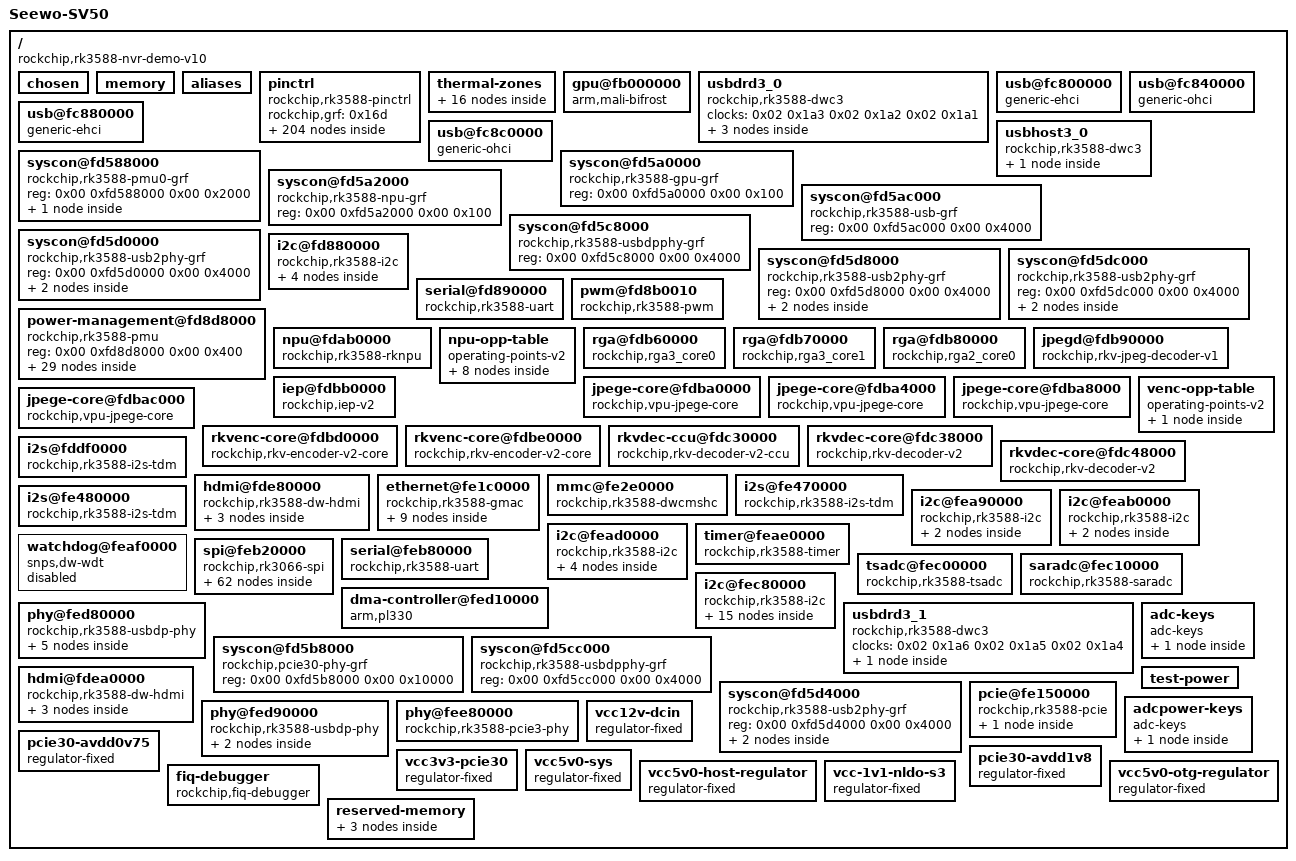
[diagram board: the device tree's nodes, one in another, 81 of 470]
/dts-v1/;

/memreserve/	0x000000000a100000 0x0000000000028000;
/ {
	compatible = "rockchip,rk3588-nvr-demo-v10\0rockchip,rk3588";
	interrupt-parent = <0x01>;
	#address-cells = <0x02>;
	#size-cells = <0x02>;
	model = "Seewo-SV50";
	
	chosen {
		bootargs = "earlycon=uart8250,mmio32,0xfeb50000 console=ttyFIQ0 irqchip.gicv3_pseudo_nmi=0 clk_gate.always_on=1 pm_domains.always_on=1";
	};

	memory {
		reg = <0x00 0x200000 0x00 0x8200000 0x00 0x9400000 0x00 0xe6c00000 0x01 0x00 0x01 0x00 0x00 0x00 0x00 0x00 0x00 0x00 0x00 0x00 0x00 0x00 0x00 0x00 0x00 0x00 0x00 0x00 0x00 0x00 0x00 0x00 0x00 0x00 0x00 0x00 0x00 0x00 0x00 0x00 0x00 0x00 0x00 0x00 0x00 0x00 0x00 0x00>;
		device_type = "memory";
	};

	aliases {
	    mmc0 = "/mmc@fe2e0000";
		ethernet ="/ethernet@fe1c0000";
	};
	
	pinctrl {
		compatible = "rockchip,rk3588-pinctrl";
		rockchip,grf = <0x16d>;
		#address-cells = <0x02>;
		#size-cells = <0x02>;
		ranges;
		phandle = <0x16e>;

		gpio@fd8a0000 {
			compatible = "rockchip,gpio-bank";
			reg = <0x00 0xfd8a0000 0x00 0x100>;
			interrupts = <0x00 0x115 0x04>;
			clocks = <0x02 0x284 0x02 0x285>;
			gpio-controller;
			#gpio-cells = <0x02>;
			gpio-ranges = <0x16e 0x00 0x00 0x20>;
			interrupt-controller;
			#interrupt-cells = <0x02>;
			phandle = <0x128>;
		};

		gpio@fec20000 {
			compatible = "rockchip,gpio-bank";
			reg = <0x00 0xfec20000 0x00 0x100>;
			interrupts = <0x00 0x116 0x04>;
			clocks = <0x02 0x7d 0x02 0x7e>;
			gpio-controller;
			#gpio-cells = <0x02>;
			gpio-ranges = <0x16e 0x00 0x20 0x20>;
			interrupt-controller;
			#interrupt-cells = <0x02>;
			phandle = <0xf1>;
		};

		gpio@fec30000 {
			compatible = "rockchip,gpio-bank";
			reg = <0x00 0xfec30000 0x00 0x100>;
			interrupts = <0x00 0x117 0x04>;
			clocks = <0x02 0x7f 0x02 0x80>;
			gpio-controller;
			#gpio-cells = <0x02>;
			gpio-ranges = <0x16e 0x00 0x40 0x20>;
			interrupt-controller;
			#interrupt-cells = <0x02>;
			phandle = <0x129>;
		};

		gpio@fec40000 {
			compatible = "rockchip,gpio-bank";
			reg = <0x00 0xfec40000 0x00 0x100>;
			interrupts = <0x00 0x118 0x04>;
			clocks = <0x02 0x81 0x02 0x82>;
			gpio-controller;
			#gpio-cells = <0x02>;
			gpio-ranges = <0x16e 0x00 0x60 0x20>;
			interrupt-controller;
			#interrupt-cells = <0x02>;
			phandle = <0xf5>;
		};

		gpio@fec50000 {
			compatible = "rockchip,gpio-bank";
			reg = <0x00 0xfec50000 0x00 0x100>;
			interrupts = <0x00 0x119 0x04>;
			clocks = <0x02 0x83 0x02 0x84>;
			gpio-controller;
			#gpio-cells = <0x02>;
			gpio-ranges = <0x16e 0x00 0x80 0x20>;
			interrupt-controller;
			#interrupt-cells = <0x02>;
			phandle = <0xe6>;
		};

		pcfg-pull-up {
			bias-pull-up;
			phandle = <0x174>;
		};

		pcfg-pull-none {
			bias-disable;
			phandle = <0x16f>;
		};

		pcfg-pull-none-drv-level-2 {
			bias-disable;
			drive-strength = <0x02>;
			phandle = <0x177>;
		};

		pcfg-pull-up-drv-level-1 {
			bias-pull-up;
			drive-strength = <0x01>;
			phandle = <0x176>;
		};

		pcfg-pull-up-drv-level-2 {
			bias-pull-up;
			drive-strength = <0x02>;
			phandle = <0x170>;
		};

		pcfg-pull-none-smt {
			bias-disable;
			input-schmitt-enable;
			phandle = <0x173>;
		};

		pcfg-pull-none-drv-level-1-smt {
			bias-disable;
			drive-strength = <0x01>;
			input-schmitt-enable;
			phandle = <0x172>;
		};

		pcfg-pull-none-drv-level-5-smt {
			bias-disable;
			drive-strength = <0x05>;
			input-schmitt-enable;
			phandle = <0x171>;
		};

		pcfg-output-high {
			output-high;
			phandle = <0x175>;
		};

		auddsm {

			auddsm-pins {
				rockchip,pins = <0x03 0x01 0x04 0x16f 0x03 0x02 0x04 0x16f 0x03 0x03 0x04 0x16f 0x03 0x04 0x04 0x16f>;
				phandle = <0x121>;
			};
		};

		bt1120 {

			bt1120-pins {
				rockchip,pins = <0x04 0x08 0x02 0x16f 0x04 0x00 0x02 0x16f 0x04 0x01 0x02 0x16f 0x04 0x02 0x02 0x16f 0x04 0x03 0x02 0x16f 0x04 0x04 0x02 0x16f 0x04 0x05 0x02 0x16f 0x04 0x06 0x02 0x16f 0x04 0x07 0x02 0x16f 0x04 0x0a 0x02 0x16f 0x04 0x0b 0x02 0x16f 0x04 0x0c 0x02 0x16f 0x04 0x0d 0x02 0x16f 0x04 0x0e 0x02 0x16f 0x04 0x0f 0x02 0x16f 0x04 0x10 0x02 0x16f 0x04 0x11 0x02 0x16f>;
				phandle = <0x59>;
			};
		};

		can0 {

			can0m0-pins {
				rockchip,pins = <0x00 0x10 0x0b 0x16f 0x00 0x0f 0x0b 0x16f>;
				phandle = <0x122>;
			};
		};

		can1 {

			can1m0-pins {
				rockchip,pins = <0x03 0x0d 0x09 0x16f 0x03 0x0e 0x09 0x16f>;
				phandle = <0x123>;
			};
		};

		can2 {

			can2m0-pins {
				rockchip,pins = <0x03 0x14 0x09 0x16f 0x03 0x15 0x09 0x16f>;
				phandle = <0x124>;
			};
		};

		dp0 {

			dp0m2-pins {
				rockchip,pins = <0x01 0x00 0x05 0x16f>;
				phandle = <0xdf>;
			};
		};

		dp1 {

			dp1m0-pins {
				rockchip,pins = <0x03 0x1d 0x05 0x16f>;
				phandle = <0x183>;
			};
		};

		gmac1 {

			gmac1-miim {
				rockchip,pins = <0x03 0x12 0x01 0x16f 0x03 0x13 0x01 0x16f>;
				phandle = <0xf6>;
			};

			gmac1-rx-bus2 {
				rockchip,pins = <0x03 0x07 0x01 0x16f 0x03 0x08 0x01 0x16f 0x03 0x09 0x01 0x16f>;
				phandle = <0xf8>;
			};

			gmac1-tx-bus2 {
				rockchip,pins = <0x03 0x0b 0x01 0x16f 0x03 0x0c 0x01 0x16f 0x03 0x0d 0x01 0x16f>;
				phandle = <0xf7>;
			};

			gmac1-rgmii-clk {
				rockchip,pins = <0x03 0x05 0x01 0x16f 0x03 0x04 0x01 0x16f>;
				phandle = <0xf9>;
			};

			gmac1-rgmii-bus {
				rockchip,pins = <0x03 0x02 0x01 0x16f 0x03 0x03 0x01 0x16f 0x03 0x00 0x01 0x16f 0x03 0x01 0x01 0x16f>;
				phandle = <0xfa>;
			};
		};

		hdmi {

			hdmim0-tx0-hpd {
				rockchip,pins = <0x01 0x05 0x05 0x16f>;
				phandle = <0xe2>;
			};

			hdmim0-tx0-scl {
				rockchip,pins = <0x04 0x0f 0x05 0x171>;
				phandle = <0xe3>;
			};

			hdmim0-tx0-sda {
				rockchip,pins = <0x04 0x10 0x05 0x172>;
				phandle = <0xe4>;
			};

			hdmim0-tx1-hpd {
				rockchip,pins = <0x01 0x06 0x05 0x16f>;
				phandle = <0x186>;
			};

			hdmim1-rx {
				rockchip,pins = <0x03 0x19 0x05 0x16f 0x03 0x1a 0x05 0x173 0x03 0x1b 0x05 0x173 0x03 0x1c 0x05 0x16f>;
				phandle = <0x190>;
			};

			hdmim1-tx1-scl {
				rockchip,pins = <0x03 0x16 0x05 0x171>;
				phandle = <0x187>;
			};

			hdmim1-tx1-sda {
				rockchip,pins = <0x03 0x15 0x05 0x172>;
				phandle = <0x188>;
			};
		};

		i2c0 {

			i2c0m2-xfer {
				rockchip,pins = <0x00 0x19 0x03 0x173 0x00 0x1a 0x03 0x173>;
				phandle = <0x60>;
			};
		};

		i2c1 {

			i2c1m2-xfer {
				rockchip,pins = <0x00 0x1c 0x09 0x173 0x00 0x1d 0x09 0x173>;
				phandle = <0x125>;
			};
		};

		i2c2 {

			i2c2m0-xfer {
				rockchip,pins = <0x00 0x0f 0x09 0x173 0x00 0x10 0x09 0x173>;
				phandle = <0x126>;
			};
		};

		i2c3 {

			i2c3m0-xfer {
				rockchip,pins = <0x01 0x11 0x09 0x173 0x01 0x10 0x09 0x173>;
				phandle = <0x127>;
			};
		};

		i2c4 {

			i2c4m3-xfer {
				rockchip,pins = <0x01 0x03 0x09 0x173 0x01 0x02 0x09 0x173>;
				phandle = <0x12a>;
			};
		};

		i2c5 {

			i2c5m0-xfer {
				rockchip,pins = <0x03 0x17 0x09 0x173 0x03 0x18 0x09 0x173>;
				phandle = <0x12b>;
			};
		};

		i2c6 {

			i2c6m0-xfer {
				rockchip,pins = <0x00 0x18 0x09 0x173 0x00 0x17 0x09 0x173>;
				phandle = <0x157>;
			};
		};

		i2c7 {

			i2c7m0-xfer {
				rockchip,pins = <0x01 0x18 0x09 0x173 0x01 0x19 0x09 0x173>;
				phandle = <0x15d>;
			};
		};

		i2c8 {

			i2c8m0-xfer {
				rockchip,pins = <0x04 0x1a 0x09 0x173 0x04 0x1b 0x09 0x173>;
				phandle = <0x15e>;
			};
		};

		i2s0 {

			i2s0-lrck {
				rockchip,pins = <0x01 0x15 0x01 0x16f>;
				phandle = <0x101>;
			};

			i2s0-sclk {
				rockchip,pins = <0x01 0x13 0x01 0x16f>;
				phandle = <0x102>;
			};

			i2s0-sdo0 {
				rockchip,pins = <0x01 0x17 0x01 0x16f>;
				phandle = <0x103>;
			};
		};

		i2s1 {

			i2s1m0-lrck {
				rockchip,pins = <0x04 0x02 0x03 0x16f>;
				phandle = <0x104>;
			};

			i2s1m0-sclk {
				rockchip,pins = <0x04 0x01 0x03 0x16f>;
				phandle = <0x105>;
			};

			i2s1m0-sdi0 {
				rockchip,pins = <0x04 0x05 0x03 0x16f>;
				phandle = <0x106>;
			};

			i2s1m0-sdi1 {
				rockchip,pins = <0x04 0x06 0x03 0x16f>;
				phandle = <0x107>;
			};

			i2s1m0-sdi2 {
				rockchip,pins = <0x04 0x07 0x03 0x16f>;
				phandle = <0x108>;
			};

			i2s1m0-sdi3 {
				rockchip,pins = <0x04 0x08 0x03 0x16f>;
				phandle = <0x109>;
			};

			i2s1m0-sdo0 {
				rockchip,pins = <0x04 0x09 0x03 0x16f>;
				phandle = <0x10a>;
			};
		};

		i2s2 {

			i2s2m1-lrck {
				rockchip,pins = <0x03 0x0e 0x03 0x16f>;
				phandle = <0x10b>;
			};

			i2s2m1-sclk {
				rockchip,pins = <0x03 0x0d 0x03 0x16f>;
				phandle = <0x10c>;
			};

			i2s2m1-sdi {
				rockchip,pins = <0x03 0x0a 0x03 0x16f>;
				phandle = <0x10d>;
			};

			i2s2m1-sdo {
				rockchip,pins = <0x03 0x0b 0x03 0x16f>;
				phandle = <0x10e>;
			};
		};

		i2s3 {

			i2s3-lrck {
				rockchip,pins = <0x03 0x02 0x03 0x16f>;
				phandle = <0x10f>;
			};

			i2s3-sclk {
				rockchip,pins = <0x03 0x01 0x03 0x16f>;
				phandle = <0x110>;
			};

			i2s3-sdi {
				rockchip,pins = <0x03 0x04 0x03 0x16f>;
				phandle = <0x111>;
			};

			i2s3-sdo {
				rockchip,pins = <0x03 0x03 0x03 0x16f>;
				phandle = <0x112>;
			};
		};

		pdm0 {

			pdm0m0-clk {
				rockchip,pins = <0x01 0x16 0x03 0x16f>;
				phandle = <0x113>;
			};

			pdm0m0-clk1 {
				rockchip,pins = <0x01 0x14 0x03 0x16f>;
				phandle = <0x114>;
			};

			pdm0m0-sdi0 {
				rockchip,pins = <0x01 0x1d 0x03 0x16f>;
				phandle = <0x115>;
			};

			pdm0m0-sdi1 {
				rockchip,pins = <0x01 0x19 0x03 0x16f>;
				phandle = <0x116>;
			};

			pdm0m0-sdi2 {
				rockchip,pins = <0x01 0x1a 0x03 0x16f>;
				phandle = <0x117>;
			};

			pdm0m0-sdi3 {
				rockchip,pins = <0x01 0x1b 0x03 0x16f>;
				phandle = <0x118>;
			};
		};

		pdm1 {

			pdm1m0-clk {
				rockchip,pins = <0x04 0x1d 0x02 0x16f>;
				phandle = <0x119>;
			};

			pdm1m0-clk1 {
				rockchip,pins = <0x04 0x1c 0x02 0x16f>;
				phandle = <0x11a>;
			};

			pdm1m0-sdi0 {
				rockchip,pins = <0x04 0x1b 0x02 0x16f>;
				phandle = <0x11b>;
			};

			pdm1m0-sdi1 {
				rockchip,pins = <0x04 0x1a 0x02 0x16f>;
				phandle = <0x11c>;
			};

			pdm1m0-sdi2 {
				rockchip,pins = <0x04 0x19 0x02 0x16f>;
				phandle = <0x11d>;
			};

			pdm1m0-sdi3 {
				rockchip,pins = <0x04 0x18 0x02 0x16f>;
				phandle = <0x11e>;
			};
		};

		pmic {

			pmic-pins {
				rockchip,pins = <0x00 0x07 0x00 0x174 0x00 0x02 0x01 0x16f 0x00 0x03 0x01 0x16f 0x00 0x11 0x01 0x16f 0x00 0x12 0x01 0x16f 0x00 0x13 0x01 0x16f 0x00 0x1e 0x01 0x16f>;
				phandle = <0x135>;
			};
		};

		pwm0 {

			pwm0m0-pins {
				rockchip,pins = <0x00 0x0f 0x03 0x16f>;
				phandle = <0x64>;
			};
		};

		pwm1 {

			pwm1m0-pins {
				rockchip,pins = <0x00 0x10 0x03 0x16f>;
				phandle = <0x65>;
			};
		};

		pwm2 {

			pwm2m0-pins {
				rockchip,pins = <0x00 0x14 0x03 0x16f>;
				phandle = <0x66>;
			};
		};

		pwm3 {

			pwm3m0-pins {
				rockchip,pins = <0x00 0x1c 0x03 0x16f>;
				phandle = <0x67>;
			};
		};

		pwm4 {

			pwm4m0-pins {
				rockchip,pins = <0x00 0x15 0x0b 0x16f>;
				phandle = <0x148>;
			};
		};

		pwm5 {

			pwm5m0-pins {
				rockchip,pins = <0x00 0x09 0x03 0x16f>;
				phandle = <0x149>;
			};
		};

		pwm6 {

			pwm6m0-pins {
				rockchip,pins = <0x00 0x17 0x0b 0x16f>;
				phandle = <0x14a>;
			};
		};

		pwm7 {

			pwm7m0-pins {
				rockchip,pins = <0x00 0x18 0x0b 0x16f>;
				phandle = <0x14b>;
			};
		};

		pwm8 {

			pwm8m0-pins {
				rockchip,pins = <0x03 0x07 0x0b 0x16f>;
				phandle = <0x14c>;
			};
		};

		pwm9 {

			pwm9m0-pins {
				rockchip,pins = <0x03 0x08 0x0b 0x16f>;
				phandle = <0x14d>;
			};
		};

		pwm10 {

			pwm10m0-pins {
				rockchip,pins = <0x03 0x00 0x0b 0x16f>;
				phandle = <0x14e>;
			};
		};

		pwm11 {

			pwm11m0-pins {
				rockchip,pins = <0x03 0x01 0x0b 0x16f>;
				phandle = <0x14f>;
			};
		};

		pwm12 {

			pwm12m0-pins {
				rockchip,pins = <0x03 0x0d 0x0b 0x16f>;
				phandle = <0x150>;
			};
		};

		pwm13 {

			pwm13m0-pins {
				rockchip,pins = <0x03 0x0e 0x0b 0x16f>;
				phandle = <0x151>;
			};
		};

		pwm14 {

			pwm14m0-pins {
				rockchip,pins = <0x03 0x12 0x0b 0x16f>;
				phandle = <0x152>;
			};
		};

		pwm15 {

			pwm15m0-pins {
				rockchip,pins = <0x03 0x13 0x0b 0x16f>;
				phandle = <0x153>;
			};
		};

		sata {

			sata1-pm-reset {
				rockchip,pins = <0x04 0x14 0x00 0x175>;
				phandle = <0x1a7>;
			};
		};

		sdio {

			sdiom1-pins {
				rockchip,pins = <0x03 0x05 0x02 0x16f 0x03 0x04 0x02 0x16f 0x03 0x00 0x02 0x16f 0x03 0x01 0x02 0x16f 0x03 0x02 0x02 0x16f 0x03 0x03 0x02 0x16f>;
				phandle = <0xff>;
			};
		};

		sdmmc {

			sdmmc-bus4 {
				rockchip,pins = <0x04 0x18 0x01 0x170 0x04 0x19 0x01 0x170 0x04 0x1a 0x01 0x170 0x04 0x1b 0x01 0x170>;
				phandle = <0xfe>;
			};

			sdmmc-clk {
				rockchip,pins = <0x04 0x1d 0x01 0x170>;
				phandle = <0xfb>;
			};

			sdmmc-cmd {
				rockchip,pins = <0x04 0x1c 0x01 0x170>;
				phandle = <0xfc>;
			};

			sdmmc-det {
				rockchip,pins = <0x00 0x04 0x01 0x174>;
				phandle = <0xfd>;
			};
		};

		spdif0 {

			spdif0m0-tx {
				rockchip,pins = <0x01 0x0e 0x03 0x16f>;
				phandle = <0x11f>;
			};
		};

		spdif1 {

			spdif1m0-tx {
				rockchip,pins = <0x01 0x0f 0x03 0x16f>;
				phandle = <0x120>;
			};
		};

		spi0 {

			spi0m0-pins {
				rockchip,pins = <0x00 0x16 0x08 0x176 0x00 0x17 0x08 0x176 0x00 0x10 0x08 0x176>;
				phandle = <0x12f>;
			};

			spi0m0-cs0 {
				rockchip,pins = <0x00 0x19 0x08 0x176>;
				phandle = <0x12d>;
			};

			spi0m0-cs1 {
				rockchip,pins = <0x00 0x0f 0x08 0x176>;
				phandle = <0x12e>;
			};
		};

		spi1 {

			spi1m1-pins {
				rockchip,pins = <0x03 0x11 0x08 0x176 0x03 0x10 0x08 0x176 0x03 0x0f 0x08 0x176>;
				phandle = <0x132>;
			};

			spi1m1-cs0 {
				rockchip,pins = <0x03 0x12 0x08 0x176>;
				phandle = <0x130>;
			};

			spi1m1-cs1 {
				rockchip,pins = <0x03 0x13 0x08 0x176>;
				phandle = <0x131>;
			};
		};

		spi2 {

			spi2m2-pins {
				rockchip,pins = <0x00 0x05 0x01 0x176 0x00 0x0b 0x01 0x176 0x00 0x06 0x01 0x176>;
				phandle = <0x134>;
			};

			spi2m2-cs0 {
				rockchip,pins = <0x00 0x09 0x01 0x176>;
				phandle = <0x133>;
			};
		};

		spi3 {

			spi3m1-pins {
				rockchip,pins = <0x04 0x0f 0x08 0x176 0x04 0x0d 0x08 0x176 0x04 0x0e 0x08 0x176>;
				phandle = <0x13e>;
			};

			spi3m1-cs0 {
				rockchip,pins = <0x04 0x10 0x08 0x176>;
				phandle = <0x13c>;
			};

			spi3m1-cs1 {
				rockchip,pins = <0x04 0x11 0x08 0x176>;
				phandle = <0x13d>;
			};
		};

		spi4 {

			spi4m0-pins {
				rockchip,pins = <0x01 0x12 0x08 0x176 0x01 0x10 0x08 0x176 0x01 0x11 0x08 0x176>;
				phandle = <0x161>;
			};

			spi4m0-cs0 {
				rockchip,pins = <0x01 0x13 0x08 0x176>;
				phandle = <0x15f>;
			};

			spi4m0-cs1 {
				rockchip,pins = <0x01 0x14 0x08 0x176>;
				phandle = <0x160>;
			};
		};

		tsadc {

			tsadc-shut {
				rockchip,pins = <0x00 0x01 0x02 0x16f>;
				phandle = <0x155>;
			};
		};

		uart0 {

			uart0m0-xfer {
				rockchip,pins = <0x00 0x14 0x04 0x174 0x00 0x15 0x04 0x174>;
				phandle = <0x63>;
			};
		};

		uart1 {

			uart1m1-xfer {
				rockchip,pins = <0x01 0x0f 0x0a 0x174 0x01 0x0e 0x0a 0x174>;
				phandle = <0x13f>;
			};
		};

		uart2 {

			uart2m0-xfer {
				rockchip,pins = <0x00 0x0e 0x0a 0x174 0x00 0x0d 0x0a 0x174>;
				phandle = <0x1bd>;
			};

			uart2m1-xfer {
				rockchip,pins = <0x04 0x19 0x0a 0x174 0x04 0x18 0x0a 0x174>;
				phandle = <0x140>;
			};
		};

		uart3 {

			uart3m1-xfer {
				rockchip,pins = <0x03 0x0e 0x0a 0x174 0x03 0x0d 0x0a 0x174>;
				phandle = <0x141>;
			};
		};

		uart4 {

			uart4m1-xfer {
				rockchip,pins = <0x03 0x18 0x0a 0x174 0x03 0x19 0x0a 0x174>;
				phandle = <0x142>;
			};
		};

		uart5 {

			uart5m0-xfer {
				rockchip,pins = <0x04 0x1c 0x0a 0x174 0x04 0x1d 0x0a 0x174>;
				phandle = <0x143>;
			};
		};

		uart6 {

			uart6m1-xfer {
				rockchip,pins = <0x01 0x00 0x0a 0x174 0x01 0x01 0x0a 0x174>;
				phandle = <0x144>;
			};
		};

		uart7 {

			uart7m1-xfer {
				rockchip,pins = <0x03 0x11 0x0a 0x174 0x03 0x10 0x0a 0x174>;
				phandle = <0x145>;
			};
		};

		uart8 {

			uart8m1-xfer {
				rockchip,pins = <0x03 0x03 0x0a 0x174 0x03 0x02 0x0a 0x174>;
				phandle = <0x146>;
			};
		};

		uart9 {

			uart9m1-xfer {
				rockchip,pins = <0x04 0x0d 0x0a 0x174 0x04 0x0c 0x0a 0x174>;
				phandle = <0x147>;
			};
		};

		gpio-func {

			tsadc-gpio-func {
				rockchip,pins = <0x00 0x01 0x00 0x16f>;
				phandle = <0x154>;
			};
		};

		gmac0 {

			gmac0-miim {
				rockchip,pins = <0x04 0x14 0x01 0x16f 0x04 0x15 0x01 0x16f>;
				phandle = <0x19b>;
			};

			gmac0-rx-bus2 {
				rockchip,pins = <0x02 0x11 0x01 0x16f 0x02 0x12 0x01 0x16f 0x04 0x12 0x01 0x16f>;
				phandle = <0x19d>;
			};

			gmac0-tx-bus2 {
				rockchip,pins = <0x02 0x0e 0x01 0x16f 0x02 0x0f 0x01 0x16f 0x02 0x10 0x01 0x16f>;
				phandle = <0x19c>;
			};

			gmac0-rgmii-clk {
				rockchip,pins = <0x02 0x08 0x01 0x16f 0x02 0x0b 0x01 0x16f>;
				phandle = <0x19e>;
			};

			gmac0-rgmii-bus {
				rockchip,pins = <0x02 0x06 0x01 0x16f 0x02 0x07 0x01 0x16f 0x02 0x09 0x01 0x16f 0x02 0x0a 0x01 0x16f>;
				phandle = <0x19f>;
			};
		};

		dp {

			dp-hdmi-ctl {
				rockchip,pins = <0x00 0x1d 0x00 0x174 0x03 0x0a 0x00 0x174>;
			};
		};

		rtc {

			rtc-int {
				rockchip,pins = <0x00 0x0a 0x00 0x174>;
			};
		};

		usb {

			vcc5v0-host-en {
				rockchip,pins = <0x04 0x08 0x00 0x16f>;
				phandle = <0x1b9>;
			};

			vcc5v0-otg-en {
				rockchip,pins = <0x04 0x03 0x00 0x16f>;
				phandle = <0x1ba>;
			};
		};

		usb-typec {

			usbc0-int {
				rockchip,pins = <0x02 0x06 0x00 0x174>;
				phandle = <0x159>;
			};
		};

		seewo {

			seewoctl-iomux {
				rockchip,pins = <0x01 0x00 0x00 0x16f 0x01 0x18 0x00 0x16f 0x01 0x04 0x00 0x16f 0x02 0x0d 0x00 0x16f 0x02 0x14 0x00 0x16f 0x02 0x11 0x00 0x16f 0x02 0x12 0x00 0x16f 0x02 0x08 0x00 0x16f 0x02 0x0c 0x00 0x16f 0x01 0x1a 0x00 0x16f 0x01 0x1b 0x00 0x16f 0x04 0x15 0x00 0x16f 0x02 0x09 0x00 0x16f 0x01 0x1d 0x00 0x16f 0x01 0x14 0x00 0x16f 0x04 0x18 0x00 0x16f 0x01 0x19 0x00 0x16f 0x04 0x1a 0x00 0x16f 0x04 0x1b 0x00 0x16f 0x01 0x0b 0x00 0x16f 0x04 0x0d 0x00 0x16f 0x04 0x0e 0x00 0x16f 0x04 0x19 0x00 0x16f>;
				phandle = <0x1bb>;
			};
		};
	};

	thermal-zones {

		soc-thermal {
			polling-delay-passive = <0x14>;
			polling-delay = <0x3e8>;
			sustainable-power = <0x834>;
			thermal-sensors = <0x49 0x00>;

			trips {

				trip-point-0 {
					temperature = <0x124f8>;
					hysteresis = <0x7d0>;
					type = "passive";
				};

				trip-point-1 {
					temperature = <0x14c08>;
					hysteresis = <0x7d0>;
					type = "passive";
					phandle = <0x4a>;
				};

				soc-crit {
					temperature = <0x1c138>;
					hysteresis = <0x7d0>;
					type = "critical";
				};
			};

			cooling-maps {

				map0 {
					trip = <0x4a>;
					cooling-device = <0x06 0xffffffff 0xffffffff>;
					contribution = <0x400>;
				};

				map1 {
					trip = <0x4a>;
					cooling-device = <0x0a 0xffffffff 0xffffffff>;
					contribution = <0x400>;
				};

				map2 {
					trip = <0x4a>;
					cooling-device = <0x0c 0xffffffff 0xffffffff>;
					contribution = <0x400>;
				};

				map3 {
					trip = <0x4a>;
					cooling-device = <0x4b 0xffffffff 0xffffffff>;
					contribution = <0x400>;
				};
			};
		};

		bigcore0-thermal {
			polling-delay-passive = <0x14>;
			polling-delay = <0x3e8>;
			thermal-sensors = <0x49 0x01>;
		};

		bigcore1-thermal {
			polling-delay-passive = <0x14>;
			polling-delay = <0x3e8>;
			thermal-sensors = <0x49 0x02>;
		};

		littlecore-thermal {
			polling-delay-passive = <0x14>;
			polling-delay = <0x3e8>;
			thermal-sensors = <0x49 0x03>;
		};

		center-thermal {
			polling-delay-passive = <0x14>;
			polling-delay = <0x3e8>;
			thermal-sensors = <0x49 0x04>;
		};

		gpu-thermal {
			polling-delay-passive = <0x14>;
			polling-delay = <0x3e8>;
			thermal-sensors = <0x49 0x05>;
		};

		npu-thermal {
			polling-delay-passive = <0x14>;
			polling-delay = <0x3e8>;
			thermal-sensors = <0x49 0x06>;
		};
	};

	gpu@fb000000 {
		compatible = "arm,mali-bifrost";
		reg = <0x00 0xfb000000 0x00 0x200000>;
		interrupts = <0x00 0x5e 0x04 0x00 0x5d 0x04 0x00 0x5c 0x04>;
		interrupt-names = "GPU\0MMU\0JOB";
		clocks = <0x0e 0x05 0x02 0x115 0x02 0x116 0x02 0x114>;
		clock-names = "clk_mali\0clk_gpu_coregroup\0clk_gpu_stacks\0clk_gpu";
		assigned-clocks = <0x0e 0x05>;
		assigned-clock-rates = <0xbebc200>;
		power-domains = <0x4c 0x0c>;
		operating-points-v2 = <0x4d>;
		#cooling-cells = <0x02>;
		dynamic-power-coefficient = <0xba6>;
		upthreshold = <0x1e>;
		downdifferential = <0x0a>;
		status = "okay";
		mali-supply = <0x4e>;
		mem-supply = <0x4e>;
		phandle = <0x4b>;
	};

	usbdrd3_0 {
		compatible = "rockchip,rk3588-dwc3\0rockchip,rk3399-dwc3";
		clocks = <0x02 0x1a3 0x02 0x1a2 0x02 0x1a1>;
		clock-names = "ref\0suspend\0bus";
		#address-cells = <0x02>;
		#size-cells = <0x02>;
		ranges;
		status = "okay";

		usb@fc000000 {
			compatible = "snps,dwc3";
			reg = <0x00 0xfc000000 0x00 0x400000>;
			interrupts = <0x00 0xdc 0x04>;
			power-domains = <0x4c 0x1f>;
			resets = <0x02 0x2a4>;
			reset-names = "usb3-otg";
			dr_mode = "peripheral";
			phys = <0x51 0x52>;
			phy-names = "usb2-phy\0usb3-phy";
			phy_type = "utmi_wide";
			snps,dis_enblslpm_quirk;
			snps,dis-u1-entry-quirk;
			snps,dis-u2-entry-quirk;
			snps,dis-u2-freeclk-exists-quirk;
			snps,dis-del-phy-power-chg-quirk;
			snps,dis-tx-ipgap-linecheck-quirk;
			snps,parkmode-disable-ss-quirk;
			quirk-skip-phy-init;
			tx-fifo-resize;
			status = "okay";

			port {
				#address-cells = <0x01>;
				#size-cells = <0x00>;

				endpoint@0 {
					reg = <0x00>;
					remote-endpoint = <0x53>;
					phandle = <0x15a>;
				};
			};
		};
	};

	usb@fc800000 {
		compatible = "generic-ehci";
		reg = <0x00 0xfc800000 0x00 0x40000>;
		interrupts = <0x00 0xd7 0x04>;
		clocks = <0x02 0x19d 0x02 0x19e 0x54>;
		clock-names = "usbhost\0arbiter\0utmi";
		phys = <0x55>;
		phy-names = "usb2-phy";
		power-domains = <0x4c 0x1f>;
		status = "okay";
	};

	usb@fc840000 {
		compatible = "generic-ohci";
		reg = <0x00 0xfc840000 0x00 0x40000>;
		interrupts = <0x00 0xd8 0x04>;
		clocks = <0x02 0x19d 0x02 0x19e 0x54>;
		clock-names = "usbhost\0arbiter\0utmi";
		phys = <0x55>;
		phy-names = "usb2-phy";
		power-domains = <0x4c 0x1f>;
		status = "okay";
	};

	usb@fc880000 {
		compatible = "generic-ehci";
		reg = <0x00 0xfc880000 0x00 0x40000>;
		interrupts = <0x00 0xda 0x04>;
		clocks = <0x02 0x19f 0x02 0x1a0 0x56>;
		clock-names = "usbhost\0arbiter\0utmi";
		phys = <0x57>;
		phy-names = "usb2-phy";
		power-domains = <0x4c 0x1f>;
		status = "okay";
	};

	usb@fc8c0000 {
		compatible = "generic-ohci";
		reg = <0x00 0xfc8c0000 0x00 0x40000>;
		interrupts = <0x00 0xdb 0x04>;
		clocks = <0x02 0x19f 0x02 0x1a0 0x56>;
		clock-names = "usbhost\0arbiter\0utmi";
		phys = <0x57>;
		phy-names = "usb2-phy";
		power-domains = <0x4c 0x1f>;
		status = "okay";
	};

	usbhost3_0 {
		compatible = "rockchip,rk3588-dwc3\0rockchip,rk3399-dwc3";
		clocks = <0x02 0x179 0x02 0x178 0x02 0x177 0x02 0x17a 0x02 0x166 0x02 0x181>;
		clock-names = "ref\0suspend\0bus\0utmi\0php\0pipe";
		#address-cells = <0x02>;
		#size-cells = <0x02>;
		ranges;
		status = "okay";

		usb@fcd00000 {
			compatible = "snps,dwc3";
			reg = <0x00 0xfcd00000 0x00 0x400000>;
			interrupts = <0x00 0xde 0x04>;
			resets = <0x02 0x237>;
			reset-names = "usb3-host";
			dr_mode = "host";
			phys = <0x58 0x04>;
			phy-names = "usb3-phy";
			phy_type = "utmi_wide";
			snps,dis_enblslpm_quirk;
			snps,dis-u2-freeclk-exists-quirk;
			snps,dis-del-phy-power-chg-quirk;
			snps,dis-tx-ipgap-linecheck-quirk;
			snps,dis_rxdet_inp3_quirk;
			snps,parkmode-disable-ss-quirk;
			status = "okay";
		};
	};

	syscon@fd588000 {
		compatible = "rockchip,rk3588-pmu0-grf\0syscon\0simple-mfd";
		reg = <0x00 0xfd588000 0x00 0x2000>;

		reboot-mode {
			compatible = "syscon-reboot-mode";
			offset = <0x80>;
			mode-bootloader = <0x5242c301>;
			mode-charge = <0x5242c30b>;
			mode-fastboot = <0x5242c309>;
			mode-loader = <0x5242c301>;
			mode-normal = <0x5242c300>;
			mode-recovery = <0x5242c303>;
			mode-ums = <0x5242c30c>;
			mode-panic = <0x5242c307>;
			mode-watchdog = <0x5242c308>;
		};
	};

	syscon@fd5a0000 {
		compatible = "rockchip,rk3588-gpu-grf\0syscon";
		reg = <0x00 0xfd5a0000 0x00 0x100>;
		phandle = <0x50>;
	};

	syscon@fd5a2000 {
		compatible = "rockchip,rk3588-npu-grf\0syscon";
		reg = <0x00 0xfd5a2000 0x00 0x100>;
		phandle = <0x9b>;
	};

	syscon@fd5ac000 {
		compatible = "rockchip,rk3588-usb-grf\0syscon";
		reg = <0x00 0xfd5ac000 0x00 0x4000>;
		phandle = <0x5c>;
	};

	syscon@fd5c8000 {
		compatible = "rockchip,rk3588-usbdpphy-grf\0syscon";
		reg = <0x00 0xfd5c8000 0x00 0x4000>;
		phandle = <0x164>;
	};

	syscon@fd5d0000 {
		compatible = "rockchip,rk3588-usb2phy-grf\0syscon\0simple-mfd";
		reg = <0x00 0xfd5d0000 0x00 0x4000>;
		#address-cells = <0x01>;
		#size-cells = <0x01>;
		phandle = <0x163>;

		usb2-phy@0 {
			compatible = "rockchip,rk3588-usb2phy";
			reg = <0x00 0x10>;
			interrupts = <0x00 0x189 0x04>;
			resets = <0x02 0xc0047 0x02 0x488>;
			reset-names = "phy\0apb";
			clocks = <0x02 0x2b5>;
			clock-names = "phyclk";
			clock-output-names = "usb480m_phy0";
			#clock-cells = <0x00>;
			rockchip,usbctrl-grf = <0x5c>;
			status = "okay";
			phandle = <0x165>;

			otg-port {
				#phy-cells = <0x00>;
				status = "okay";
				vbus-supply = <0x5d>;
				rockchip,typec-vbus-det;
				rockchip,dis-u2-susphy;
				phandle = <0x51>;
			};
		};
	};

	syscon@fd5d8000 {
		compatible = "rockchip,rk3588-usb2phy-grf\0syscon\0simple-mfd";
		reg = <0x00 0xfd5d8000 0x00 0x4000>;
		#address-cells = <0x01>;
		#size-cells = <0x01>;

		usb2-phy@8000 {
			compatible = "rockchip,rk3588-usb2phy";
			reg = <0x8000 0x10>;
			interrupts = <0x00 0x187 0x04>;
			resets = <0x02 0xc0049 0x02 0x48a>;
			reset-names = "phy\0apb";
			clocks = <0x02 0x2b5>;
			clock-names = "phyclk";
			clock-output-names = "usb480m_phy2";
			#clock-cells = <0x00>;
			status = "okay";
			phandle = <0x54>;

			host-port {
				#phy-cells = <0x00>;
				status = "okay";
				phy-supply = <0x5e>;
				phandle = <0x55>;
			};
		};
	};

	syscon@fd5dc000 {
		compatible = "rockchip,rk3588-usb2phy-grf\0syscon\0simple-mfd";
		reg = <0x00 0xfd5dc000 0x00 0x4000>;
		#address-cells = <0x01>;
		#size-cells = <0x01>;

		usb2-phy@c000 {
			compatible = "rockchip,rk3588-usb2phy";
			reg = <0xc000 0x10>;
			interrupts = <0x00 0x188 0x04>;
			resets = <0x02 0xc004a 0x02 0x48b>;
			reset-names = "phy\0apb";
			clocks = <0x02 0x2b5>;
			clock-names = "phyclk";
			clock-output-names = "usb480m_phy3";
			#clock-cells = <0x00>;
			status = "okay";
			phandle = <0x56>;

			host-port {
				#phy-cells = <0x00>;
				status = "okay";
				phy-supply = <0x5e>;
				phandle = <0x57>;
			};
		};
	};

	i2c@fd880000 {
		compatible = "rockchip,rk3588-i2c\0rockchip,rk3399-i2c";
		reg = <0x00 0xfd880000 0x00 0x1000>;
		clocks = <0x02 0x287 0x02 0x286>;
		clock-names = "i2c\0pclk";
		interrupts = <0x00 0x13d 0x04>;
		pinctrl-names = "default";
		pinctrl-0 = <0x60>;
		#address-cells = <0x01>;
		#size-cells = <0x00>;
		status = "okay";

		rk8602@42 {
			compatible = "rockchip,rk8602";
			reg = <0x42>;
			vin-supply = <0x61>;
			regulator-compatible = "rk860x-reg";
			regulator-name = "vdd_cpu_big0_s0";
			regulator-min-microvolt = <0x86470>;
			regulator-max-microvolt = <0x100590>;
			regulator-ramp-delay = <0x8fc>;
			rockchip,suspend-voltage-selector = <0x01>;
			regulator-boot-on;
			regulator-always-on;
			phandle = <0x12>;

			regulator-state-mem {
				regulator-off-in-suspend;
			};
		};

		rk8603@43 {
			compatible = "rockchip,rk8603";
			reg = <0x43>;
			vin-supply = <0x61>;
			regulator-compatible = "rk860x-reg";
			regulator-name = "vdd_cpu_big1_s0";
			regulator-min-microvolt = <0x86470>;
			regulator-max-microvolt = <0x100590>;
			regulator-ramp-delay = <0x8fc>;
			rockchip,suspend-voltage-selector = <0x01>;
			regulator-boot-on;
			regulator-always-on;
			phandle = <0x16>;

			regulator-state-mem {
				regulator-off-in-suspend;
			};
		};
	};

	serial@fd890000 {
		compatible = "rockchip,rk3588-uart\0snps,dw-apb-uart";
		reg = <0x00 0xfd890000 0x00 0x100>;
		interrupts = <0x00 0x14b 0x04>;
		clocks = <0x02 0x2ae 0x02 0x2af>;
		clock-names = "baudclk\0apb_pclk";
		reg-shift = <0x02>;
		reg-io-width = <0x04>;
		dmas = <0x62 0x06 0x62 0x07>;
		pinctrl-names = "default";
		pinctrl-0 = <0x63>;
		status = "okay";
	};

	pwm@fd8b0010 {
		compatible = "rockchip,rk3588-pwm\0rockchip,rk3328-pwm";
		reg = <0x00 0xfd8b0010 0x00 0x10>;
		#pwm-cells = <0x03>;
		pinctrl-names = "active";
		pinctrl-0 = <0x65>;
		clocks = <0x02 0x2a5 0x02 0x2a4>;
		clock-names = "pwm\0pclk";
		status = "okay";
		phandle = <0x1bc>;
	};

	power-management@fd8d8000 {
		compatible = "rockchip,rk3588-pmu\0syscon\0simple-mfd";
		reg = <0x00 0xfd8d8000 0x00 0x400>;
		phandle = <0xbe>;

		power-controller {
			compatible = "rockchip,rk3588-power-controller";
			#power-domain-cells = <0x01>;
			#address-cells = <0x01>;
			#size-cells = <0x00>;
			status = "okay";
			phandle = <0x4c>;

			power-domain@8 {
				reg = <0x08>;
				#address-cells = <0x01>;
				#size-cells = <0x00>;

				power-domain@9 {
					reg = <0x09>;
					#address-cells = <0x01>;
					#size-cells = <0x00>;
					clocks = <0x02 0x12f 0x02 0x131 0x02 0x130 0x02 0x126>;
					pm_qos = <0x68 0x69 0x6a>;

					power-domain@10 {
						reg = <0x0a>;
						clocks = <0x02 0x12f 0x02 0x131 0x02 0x130>;
						pm_qos = <0x6b>;
					};

					power-domain@11 {
						reg = <0x0b>;
						clocks = <0x02 0x12f 0x02 0x131 0x02 0x130>;
						pm_qos = <0x6c>;
					};
				};
			};

			power-domain@12 {
				reg = <0x0c>;
				clocks = <0x02 0x114 0x02 0x115 0x02 0x116>;
				pm_qos = <0x6d 0x6e 0x6f 0x70>;
			};

			power-domain@13 {
				reg = <0x0d>;
				#address-cells = <0x01>;
				#size-cells = <0x00>;

				power-domain@14 {
					reg = <0x0e>;
					clocks = <0x02 0x18f 0x02 0x1be 0x02 0x1bc 0x02 0x190 0x02 0x18e>;
					pm_qos = <0x71>;
				};

				power-domain@15 {
					reg = <0x0f>;
					clocks = <0x02 0x194 0x02 0x1be 0x02 0x1bc 0x02 0x195>;
					pm_qos = <0x72>;
				};

				power-domain@16 {
					reg = <0x10>;
					#address-cells = <0x01>;
					#size-cells = <0x00>;
					clocks = <0x02 0x1c4 0x02 0x1c5>;
					pm_qos = <0x73 0x74 0x75>;

					power-domain@17 {
						reg = <0x11>;
						clocks = <0x02 0x1c9 0x02 0x1c4 0x02 0x1c5 0x02 0x1ca>;
						pm_qos = <0x76 0x77 0x78>;
					};
				};
			};

			power-domain@21 {
				reg = <0x15>;
				#address-cells = <0x01>;
				#size-cells = <0x00>;
				clocks = <0x02 0x1be 0x02 0x1bd 0x02 0x1bc 0x02 0x1bf 0x02 0x1aa 0x02 0x1a9 0x02 0x1ac 0x02 0x1ad 0x02 0x1ae 0x02 0x1af 0x02 0x1b0 0x02 0x1b1 0x02 0x1b2 0x02 0x1b3 0x02 0x1b4 0x02 0x1b5 0x02 0x1b7 0x02 0x1b6>;
				pm_qos = <0x79 0x7a 0x7b 0x7c 0x7d 0x7e 0x7f 0x80>;

				power-domain@23 {
					reg = <0x17>;
					clocks = <0x02 0x4b 0x02 0x49 0x02 0x1be>;
					pm_qos = <0x81>;
				};

				power-domain@14 {
					reg = <0x0e>;
					clocks = <0x02 0x18f 0x02 0x1be 0x02 0x1bc 0x02 0x190>;
					pm_qos = <0x71>;
				};

				power-domain@15 {
					reg = <0x0f>;
					clocks = <0x02 0x194 0x02 0x1be 0x02 0x1bc>;
					pm_qos = <0x72>;
				};

				power-domain@22 {
					reg = <0x16>;
					clocks = <0x02 0x1ba 0x02 0x1b9>;
					pm_qos = <0x82>;
				};
			};

			power-domain@24 {
				reg = <0x18>;
				#address-cells = <0x01>;
				#size-cells = <0x00>;
				clocks = <0x02 0x26e 0x02 0x26d 0x02 0x270>;
				pm_qos = <0x83 0x84>;

				power-domain@25 {
					reg = <0x19>;
					clocks = <0x02 0x1f6 0x02 0x1f7 0x02 0x1f5 0x02 0x1f3 0x02 0x1ee 0x02 0x1ed 0x02 0x26d>;
					pm_qos = <0x85>;
				};
			};

			power-domain@26 {
				reg = <0x1a>;
				clocks = <0x02 0x22e 0x02 0x22f 0x02 0x22d 0x02 0x218 0x02 0x217 0x02 0x22b 0x02 0x264>;
				pm_qos = <0x86 0x87>;
			};

			power-domain@27 {
				reg = <0x1b>;
				#address-cells = <0x01>;
				#size-cells = <0x00>;
				clocks = <0x02 0x1e1 0x02 0x1e2 0x02 0x1df 0x02 0x1de 0x02 0x1e5 0x02 0x1e4>;
				pm_qos = <0x88 0x89 0x8a 0x8b>;

				power-domain@28 {
					reg = <0x1c>;
					clocks = <0x02 0x121 0x02 0x120 0x02 0x1e1 0x02 0x1e2>;
					pm_qos = <0x8c 0x8d>;
				};

				power-domain@29 {
					reg = <0x1d>;
					clocks = <0x02 0x1d6 0x02 0x1d5 0x02 0x1d9 0x02 0x1d8 0x02 0x1e2>;
					pm_qos = <0x8e 0x8f>;
				};
			};

			power-domain@30 {
				reg = <0x1e>;
				clocks = <0x02 0x189 0x02 0x18a>;
				pm_qos = <0x90>;
			};

			power-domain@31 {
				reg = <0x1f>;
				clocks = <0x02 0x166 0x02 0x19b 0x02 0x19c 0x02 0x19d 0x02 0x19e 0x02 0x19f 0x02 0x1a0>;
				pm_qos = <0x91 0x92 0x93 0x94>;
			};

			power-domain@33 {
				reg = <0x21>;
				clocks = <0x02 0x166 0x02 0x169 0x02 0x16a>;
			};

			power-domain@34 {
				reg = <0x22>;
				clocks = <0x02 0x166 0x02 0x169 0x02 0x16a>;
			};

			power-domain@37 {
				reg = <0x25>;
				clocks = <0x02 0x199 0x02 0x140>;
				pm_qos = <0x95>;
			};

			power-domain@38 {
				reg = <0x26>;
				clocks = <0x02 0x3c 0x02 0x3d>;
			};

			power-domain@40 {
				reg = <0x28>;
				pm_qos = <0x96>;
			};
		};
	};

	npu@fdab0000 {
		compatible = "rockchip,rk3588-rknpu";
		reg = <0x00 0xfdab0000 0x00 0x10000 0x00 0xfdac0000 0x00 0x10000 0x00 0xfdad0000 0x00 0x10000>;
		interrupts = <0x00 0x6e 0x04 0x00 0x6f 0x04 0x00 0x70 0x04>;
		interrupt-names = "npu0_irq\0npu1_irq\0npu2_irq";
		clocks = <0x0e 0x06 0x02 0x12d 0x02 0x122 0x02 0x124 0x02 0x12e 0x02 0x123 0x02 0x125 0x02 0x131>;
		clock-names = "clk_npu\0aclk0\0aclk1\0aclk2\0hclk0\0hclk1\0hclk2\0pclk";
		assigned-clocks = <0x0e 0x06>;
		assigned-clock-rates = <0xbebc200>;
		resets = <0x02 0x1e6 0x02 0x1b0 0x02 0x1c0 0x02 0x1e8 0x02 0x1b2 0x02 0x1c2>;
		reset-names = "srst_a0\0srst_a1\0srst_a2\0srst_h0\0srst_h1\0srst_h2";
		power-domains = <0x4c 0x09 0x4c 0x0a 0x4c 0x0b>;
		power-domain-names = "npu0\0npu1\0npu2";
		operating-points-v2 = <0x97>;
		iommus = <0x98>;
		status = "okay";
		rknpu-supply = <0x99>;
		mem-supply = <0x99>;
	};

	npu-opp-table {
		compatible = "operating-points-v2";
		nvmem-cells = <0x9a>;
		nvmem-cell-names = "leakage";
		rockchip,pvtm-voltage-sel = <0x00 0x32f 0x00 0x330 0x343 0x01 0x344 0x35c 0x02 0x35d 0x375 0x03 0x376 0x38e 0x04 0x38f 0x270f 0x05>;
		rockchip,pvtm-pvtpll;
		rockchip,pvtm-offset = <0x50>;
		rockchip,pvtm-sample-time = <0x44c>;
		rockchip,pvtm-freq = "\0\f5";
		rockchip,pvtm-volt = <0xb71b0>;
		rockchip,pvtm-ref-temp = <0x19>;
		rockchip,pvtm-temp-prop = <0xffffff8f 0xffffff8f>;
		rockchip,pvtm-thermal-zone = "npu-thermal";
		clocks = <0x02 0x12a>;
		clock-names = "pclk";
		rockchip,grf = <0x9b>;
		volt-mem-read-margin = <0xd0bd8 0x01 0xbac48 0x02 0xa4cb8 0x03 0x78d98 0x04>;
		low-volt-read-margin = <0x04>;
		intermediate-threshold-freq = <0x7a120>;
		rockchip,init-freq = <0xf4240>;
		rockchip,temp-hysteresis = <0x1388>;
		rockchip,low-temp = <0x2710>;
		rockchip,low-temp-min-volt = <0xb71b0>;
		rockchip,high-temp = <0x14c08>;
		rockchip,high-temp-max-freq = "\0\f5";
		phandle = <0x97>;

		opp-300000000 {
			opp-hz = <0x00 0x11e1a300>;
			opp-microvolt = <0xa4cb8 0xa4cb8 0xcf850 0xa4cb8 0xa4cb8 0xcf850>;
		};

		opp-400000000 {
			opp-hz = <0x00 0x17d78400>;
			opp-microvolt = <0xa4cb8 0xa4cb8 0xcf850 0xa4cb8 0xa4cb8 0xcf850>;
		};

		opp-500000000 {
			opp-hz = <0x00 0x1dcd6500>;
			opp-microvolt = <0xa4cb8 0xa4cb8 0xcf850 0xa4cb8 0xa4cb8 0xcf850>;
		};

		opp-600000000 {
			opp-hz = <0x00 0x23c34600>;
			opp-microvolt = <0xa4cb8 0xa4cb8 0xcf850 0xa4cb8 0xa4cb8 0xcf850>;
		};

		opp-700000000 {
			opp-hz = <0x00 0x29b92700>;
			opp-microvolt = <0xaae60 0xaae60 0xcf850 0xaae60 0xaae60 0xcf850>;
			opp-microvolt-L3 = <0xa7d8c 0xa7d8c 0xcf850 0xa7d8c 0xa7d8c 0xcf850>;
			opp-microvolt-L4 = <0xa4cb8 0xa4cb8 0xcf850 0xa4cb8 0xa4cb8 0xcf850>;
			opp-microvolt-L5 = <0xa4cb8 0xa4cb8 0xcf850 0xa4cb8 0xa4cb8 0xcf850>;
		};

		opp-800000000 {
			opp-hz = <0x00 0x2faf0800>;
			opp-microvolt = <0xb71b0 0xb71b0 0xcf850 0xb71b0 0xb71b0 0xcf850>;
			opp-microvolt-L2 = <0xb40dc 0xb40dc 0xcf850 0xb40dc 0xb40dc 0xcf850>;
			opp-microvolt-L3 = <0xb1008 0xb1008 0xcf850 0xb1008 0xb1008 0xcf850>;
			opp-microvolt-L4 = <0xadf34 0xadf34 0xcf850 0xadf34 0xadf34 0xcf850>;
			opp-microvolt-L5 = <0xaae60 0xaae60 0xcf850 0xaae60 0xaae60 0xcf850>;
		};

		opp-900000000 {
			opp-hz = <0x00 0x35a4e900>;
			opp-microvolt = <0xc3500 0xc3500 0xcf850 0xc3500 0xc3500 0xcf850>;
			opp-microvolt-L1 = <0xc042c 0xc042c 0xcf850 0xc042c 0xc042c 0xcf850>;
			opp-microvolt-L2 = <0xbd358 0xbd358 0xcf850 0xbd358 0xbd358 0xcf850>;
			opp-microvolt-L3 = <0xba284 0xba284 0xcf850 0xba284 0xba284 0xcf850>;
			opp-microvolt-L4 = <0xb71b0 0xb71b0 0xcf850 0xb71b0 0xb71b0 0xcf850>;
			opp-microvolt-L5 = <0xb40dc 0xb40dc 0xcf850 0xb40dc 0xb40dc 0xcf850>;
		};

		opp-1000000000 {
			opp-hz = <0x00 0x3b9aca00>;
			opp-microvolt = <0xcf850 0xcf850 0xcf850 0xcf850 0xcf850 0xcf850>;
			opp-microvolt-L1 = <0xcc77c 0xcc77c 0xcf850 0xcc77c 0xcc77c 0xcf850>;
			opp-microvolt-L2 = <0xc96a8 0xc96a8 0xcf850 0xc96a8 0xc96a8 0xcf850>;
			opp-microvolt-L3 = <0xc65d4 0xc65d4 0xcf850 0xc65d4 0xc65d4 0xcf850>;
			opp-microvolt-L4 = <0xc3500 0xc3500 0xcf850 0xc3500 0xc3500 0xcf850>;
			opp-microvolt-L5 = <0xc042c 0xc042c 0xcf850 0xc042c 0xc042c 0xcf850>;
		};
	};

	rga@fdb60000 {
		compatible = "rockchip,rga3_core0";
		reg = <0x00 0xfdb60000 0x00 0x1000>;
		interrupts = <0x00 0x72 0x04>;
		interrupt-names = "rga3_core0_irq";
		clocks = <0x02 0x1ba 0x02 0x1b9 0x02 0x1bb>;
		clock-names = "aclk_rga3_0\0hclk_rga3_0\0clk_rga3_0";
		power-domains = <0x4c 0x16>;
		iommus = <0x9e>;
		status = "okay";
	};

	rga@fdb70000 {
		compatible = "rockchip,rga3_core1";
		reg = <0x00 0xfdb70000 0x00 0x1000>;
		interrupts = <0x00 0x73 0x04>;
		interrupt-names = "rga3_core1_irq";
		clocks = <0x02 0x18a 0x02 0x189 0x02 0x18b>;
		clock-names = "aclk_rga3_1\0hclk_rga3_1\0clk_rga3_1";
		power-domains = <0x4c 0x1e>;
		iommus = <0x9f>;
		status = "okay";
	};

	rga@fdb80000 {
		compatible = "rockchip,rga2_core0";
		reg = <0x00 0xfdb80000 0x00 0x1000>;
		interrupts = <0x00 0x74 0x04>;
		interrupt-names = "rga2_irq";
		clocks = <0x02 0x1b7 0x02 0x1b6 0x02 0x1b8>;
		clock-names = "aclk_rga2\0hclk_rga2\0clk_rga2";
		power-domains = <0x4c 0x15>;
		status = "okay";
	};

	jpegd@fdb90000 {
		compatible = "rockchip,rkv-jpeg-decoder-v1";
		reg = <0x00 0xfdb90000 0x00 0x400>;
		interrupts = <0x00 0x81 0x04>;
		interrupt-names = "irq_jpegd";
		clocks = <0x02 0x1b4 0x02 0x1b5>;
		clock-names = "aclk_vcodec\0hclk_vcodec";
		rockchip,normal-rates = <0x23c34600 0x00>;
		assigned-clocks = <0x02 0x1b4>;
		assigned-clock-rates = <0x23c34600>;
		resets = <0x02 0x2d2 0x02 0x2d3>;
		reset-names = "video_a\0video_h";
		rockchip,skip-pmu-idle-request;
		iommus = <0xa0>;
		rockchip,srv = <0x9d>;
		rockchip,taskqueue-node = <0x01>;
		power-domains = <0x4c 0x15>;
		status = "okay";
	};

	jpege-core@fdba0000 {
		compatible = "rockchip,vpu-jpege-core";
		reg = <0x00 0xfdba0000 0x00 0x400>;
		interrupts = <0x00 0x7a 0x04>;
		interrupt-names = "irq_jpege0";
		clocks = <0x02 0x1ac 0x02 0x1ad>;
		clock-names = "aclk_vcodec\0hclk_vcodec";
		rockchip,normal-rates = <0x2367b880 0x00>;
		assigned-clocks = <0x02 0x1ac>;
		assigned-clock-rates = <0x2367b880>;
		resets = <0x02 0x2ca 0x02 0x2cb>;
		reset-names = "video_a\0video_h";
		rockchip,skip-pmu-idle-request;
		iommus = <0xa1>;
		rockchip,srv = <0x9d>;
		rockchip,taskqueue-node = <0x02>;
		rockchip,ccu = <0xa2>;
		power-domains = <0x4c 0x15>;
		status = "okay";
	};

	jpege-core@fdba4000 {
		compatible = "rockchip,vpu-jpege-core";
		reg = <0x00 0xfdba4000 0x00 0x400>;
		interrupts = <0x00 0x7c 0x04>;
		interrupt-names = "irq_jpege1";
		clocks = <0x02 0x1ae 0x02 0x1af>;
		clock-names = "aclk_vcodec\0hclk_vcodec";
		rockchip,normal-rates = <0x2367b880 0x00>;
		assigned-clocks = <0x02 0x1ae>;
		assigned-clock-rates = <0x2367b880>;
		resets = <0x02 0x2cc 0x02 0x2cd>;
		reset-names = "video_a\0video_h";
		rockchip,skip-pmu-idle-request;
		iommus = <0xa3>;
		rockchip,srv = <0x9d>;
		rockchip,taskqueue-node = <0x02>;
		rockchip,ccu = <0xa2>;
		power-domains = <0x4c 0x15>;
		status = "okay";
	};

	jpege-core@fdba8000 {
		compatible = "rockchip,vpu-jpege-core";
		reg = <0x00 0xfdba8000 0x00 0x400>;
		interrupts = <0x00 0x7e 0x04>;
		interrupt-names = "irq_jpege2";
		clocks = <0x02 0x1b0 0x02 0x1b1>;
		clock-names = "aclk_vcodec\0hclk_vcodec";
		rockchip,normal-rates = <0x2367b880 0x00>;
		assigned-clocks = <0x02 0x1b0>;
		assigned-clock-rates = <0x2367b880>;
		resets = <0x02 0x2ce 0x02 0x2cf>;
		reset-names = "video_a\0video_h";
		rockchip,skip-pmu-idle-request;
		iommus = <0xa4>;
		rockchip,srv = <0x9d>;
		rockchip,taskqueue-node = <0x02>;
		rockchip,ccu = <0xa2>;
		power-domains = <0x4c 0x15>;
		status = "okay";
	};

	jpege-core@fdbac000 {
		compatible = "rockchip,vpu-jpege-core";
		reg = <0x00 0xfdbac000 0x00 0x400>;
		interrupts = <0x00 0x80 0x04>;
		interrupt-names = "irq_jpege3";
		clocks = <0x02 0x1b2 0x02 0x1b3>;
		clock-names = "aclk_vcodec\0hclk_vcodec";
		rockchip,normal-rates = <0x2367b880 0x00>;
		assigned-clocks = <0x02 0x1b2>;
		assigned-clock-rates = <0x2367b880>;
		resets = <0x02 0x2d0 0x02 0x2d1>;
		reset-names = "video_a\0video_h";
		rockchip,skip-pmu-idle-request;
		iommus = <0xa5>;
		rockchip,srv = <0x9d>;
		rockchip,taskqueue-node = <0x02>;
		rockchip,ccu = <0xa2>;
		power-domains = <0x4c 0x15>;
		status = "okay";
	};
	
	iep@fdbb0000 {
		compatible = "rockchip,iep-v2";
		reg = <0x00 0xfdbb0000 0x00 0x500>;
		interrupts = <0x00 0x75 0x04>;
		interrupt-names = "irq_iep";
		clocks = <0x02 0x1aa 0x02 0x1a9 0x02 0x1ab>;
		clock-names = "aclk\0hclk\0sclk";
		resets = <0x02 0x2d5 0x02 0x2d4 0x02 0x2d6>;
		reset-names = "rst_a\0rst_h\0rst_s";
		rockchip,skip-pmu-idle-request;
		power-domains = <0x4c 0x15>;
		rockchip,srv = <0x9d>;
		rockchip,taskqueue-node = <0x06>;
		iommus = <0xa6>;
		status = "okay";
	};

	rkvenc-core@fdbd0000 {
		compatible = "rockchip,rkv-encoder-v2-core";
		reg = <0x00 0xfdbd0000 0x00 0x6000>;
		interrupts = <0x00 0x65 0x04>;
		interrupt-names = "irq_rkvenc0";
		clocks = <0x02 0x1c5 0x02 0x1c4 0x02 0x1c6>;
		clock-names = "aclk_vcodec\0hclk_vcodec\0clk_core";
		rockchip,normal-rates = <0x23c34600 0x00 0x2faf0800>;
		assigned-clocks = <0x02 0x1c5 0x02 0x1c6>;
		assigned-clock-rates = <0x23c34600 0x2faf0800>;
		resets = <0x02 0x2f5 0x02 0x2f4 0x02 0x2f6>;
		reset-names = "video_a\0video_h\0video_core";
		rockchip,skip-pmu-idle-request;
		iommus = <0xa7>;
		rockchip,srv = <0x9d>;
		rockchip,ccu = <0xa8>;
		rockchip,taskqueue-node = <0x07>;
		rockchip,task-capacity = <0x08>;
		power-domains = <0x4c 0x10>;
		operating-points-v2 = <0xa9>;
		status = "okay";
		venc-supply = <0xaa>;
		mem-supply = <0xaa>;
	};

	rkvenc-core@fdbe0000 {
		compatible = "rockchip,rkv-encoder-v2-core";
		reg = <0x00 0xfdbe0000 0x00 0x6000>;
		interrupts = <0x00 0x68 0x04>;
		interrupt-names = "irq_rkvenc1";
		clocks = <0x02 0x1ca 0x02 0x1c9 0x02 0x1cb>;
		clock-names = "aclk_vcodec\0hclk_vcodec\0clk_core";
		rockchip,normal-rates = <0x23c34600 0x00 0x2faf0800>;
		assigned-clocks = <0x02 0x1ca 0x02 0x1cb>;
		assigned-clock-rates = <0x23c34600 0x2faf0800>;
		resets = <0x02 0x305 0x02 0x304 0x02 0x306>;
		reset-names = "video_a\0video_h\0video_core";
		rockchip,skip-pmu-idle-request;
		iommus = <0xab>;
		rockchip,srv = <0x9d>;
		rockchip,ccu = <0xa8>;
		rockchip,taskqueue-node = <0x07>;
		rockchip,task-capacity = <0x08>;
		power-domains = <0x4c 0x11>;
		operating-points-v2 = <0xa9>;
		status = "okay";
		venc-supply = <0xaa>;
		mem-supply = <0xaa>;
	};

	venc-opp-table {
		compatible = "operating-points-v2";
		nvmem-cells = <0xac>;
		nvmem-cell-names = "leakage";
		rockchip,leakage-voltage-sel = <0x01 0x08 0x00 0x09 0x14 0x01 0x15 0xfe 0x02>;
		rockchip,grf = <0xad>;
		volt-mem-read-margin = <0xd0bd8 0x01 0xbac48 0x02 0xa4cb8 0x03 0x78d98 0x04>;
		phandle = <0xa9>;

		opp-800000000 {
			opp-hz = <0x00 0x2faf0800>;
			opp-microvolt = <0xb71b0 0xb71b0 0xcf850 0xb71b0 0xb71b0 0xcf850>;
			opp-microvolt-L0 = <0xc3500 0xc3500 0xcf850 0xc3500 0xc3500 0xcf850>;
			opp-microvolt-L1 = <0xbd358 0xbd358 0xcf850 0xbd358 0xbd358 0xcf850>;
			opp-microvolt-L2 = <0xb71b0 0xb71b0 0xcf850 0xb71b0 0xb71b0 0xcf850>;
		};
	};

	rkvdec-ccu@fdc30000 {
		compatible = "rockchip,rkv-decoder-v2-ccu";
		reg = <0x00 0xfdc30000 0x00 0x100>;
		reg-names = "ccu";
		clocks = <0x02 0x18e>;
		clock-names = "aclk_ccu";
		assigned-clocks = <0x02 0x18e>;
		assigned-clock-rates = <0x23c34600>;
		resets = <0x02 0x282>;
		reset-names = "video_ccu";
		rockchip,skip-pmu-idle-request;
		power-domains = <0x4c 0x0e>;
		status = "okay";
		phandle = <0xaf>;
	};

	rkvdec-core@fdc38000 {
		compatible = "rockchip,rkv-decoder-v2";
		reg = <0x00 0xfdc38100 0x00 0x400 0x00 0xfdc38000 0x00 0x100>;
		reg-names = "regs\0link";
		interrupts = <0x00 0x5f 0x04>;
		interrupt-names = "irq_rkvdec0";
		clocks = <0x02 0x190 0x02 0x18f 0x02 0x193 0x02 0x191 0x02 0x192>;
		clock-names = "aclk_vcodec\0hclk_vcodec\0clk_core\0clk_cabac\0clk_hevc_cabac";
		rockchip,normal-rates = <0x2faf0800 0x00 0x23c34600 0x23c34600 0x3b9aca00>;
		assigned-clocks = <0x02 0x190 0x02 0x193 0x02 0x191 0x02 0x192>;
		assigned-clock-rates = <0x2faf0800 0x23c34600 0x23c34600 0x3b9aca00>;
		resets = <0x02 0x284 0x02 0x283 0x02 0x289 0x02 0x287 0x02 0x288>;
		reset-names = "video_a\0video_h\0video_core\0video_cabac\0video_hevc_cabac";
		rockchip,skip-pmu-idle-request;
		iommus = <0xae>;
		rockchip,srv = <0x9d>;
		rockchip,ccu = <0xaf>;
		rockchip,core-mask = <0x10001>;
		rockchip,taskqueue-node = <0x09>;
		rockchip,sram = <0xb0>;
		rockchip,rcb-iova = <0x10000000 0x100000>;
		rockchip,rcb-min-width = <0x200>;
		power-domains = <0x4c 0x0e>;
		status = "okay";
	};

	rkvdec-core@fdc48000 {
		compatible = "rockchip,rkv-decoder-v2";
		reg = <0x00 0xfdc48100 0x00 0x400 0x00 0xfdc48000 0x00 0x100>;
		reg-names = "regs\0link";
		interrupts = <0x00 0x61 0x04>;
		interrupt-names = "irq_rkvdec1";
		clocks = <0x02 0x195 0x02 0x194 0x02 0x198 0x02 0x196 0x02 0x197>;
		clock-names = "aclk_vcodec\0hclk_vcodec\0clk_core\0clk_cabac\0clk_hevc_cabac";
		rockchip,normal-rates = <0x2faf0800 0x00 0x23c34600 0x23c34600 0x3b9aca00>;
		assigned-clocks = <0x02 0x195 0x02 0x198 0x02 0x196 0x02 0x197>;
		assigned-clock-rates = <0x2faf0800 0x23c34600 0x23c34600 0x3b9aca00>;
		resets = <0x02 0x293 0x02 0x292 0x02 0x298 0x02 0x296 0x02 0x297>;
		reset-names = "video_a\0video_h\0video_core\0video_cabac\0video_hevc_cabac";
		rockchip,skip-pmu-idle-request;
		iommus = <0xb1>;
		rockchip,srv = <0x9d>;
		rockchip,ccu = <0xaf>;
		rockchip,core-mask = <0x20002>;
		rockchip,taskqueue-node = <0x09>;
		rockchip,sram = <0xb2>;
		rockchip,rcb-iova = <0x10100000 0x100000>;
		rockchip,rcb-min-width = <0x200>;
		power-domains = <0x4c 0x0f>;
		status = "okay";
	};

	i2s@fddf0000 {
		compatible = "rockchip,rk3588-i2s-tdm";
		reg = <0x00 0xfddf0000 0x00 0x1000>;
		interrupts = <0x00 0xb9 0x04>;
		clocks = <0x02 0x246 0x02 0x246 0x02 0x248>;
		clock-names = "mclk_tx\0mclk_rx\0hclk";
		assigned-clocks = <0x02 0x243>;
		assigned-clock-parents = <0x02 0x05>;
		dmas = <0xd7 0x02>;
		dma-names = "tx";
		power-domains = <0x4c 0x1a>;
		resets = <0x02 0x3e8>;
		reset-names = "tx-m";
		rockchip,playback-only;
		#sound-dai-cells = <0x00>;
		status = "okay";
		phandle = <0x1ae>;
	};

	hdmi@fde80000 {
		compatible = "rockchip,rk3588-dw-hdmi";
		reg = <0x00 0xfde80000 0x00 0x20000>;
		interrupts = <0x00 0xa9 0x04 0x00 0xaa 0x04 0x00 0xab 0x04 0x00 0xac 0x04 0x00 0x168 0x04>;
		clocks = <0x02 0x221 0x02 0x265 0x02 0x222 0x02 0x223 0x02 0x246 0x02 0x274 0x02 0x275 0x02 0x276 0x02 0x277 0x05 0x2e>;
		clock-names = "pclk\0hpd\0earc\0hdmitx_ref\0aud\0dclk_vp0\0dclk_vp1\0dclk_vp2\0dclk_vp3\0hclk_vo1\0link_clk";
		resets = <0x02 0x3d0 0x02 0x49c>;
		reset-names = "ref\0hdp";
		power-domains = <0x4c 0x1a>;
		pinctrl-names = "default";
		pinctrl-0 = <0xe2 0xe3 0xe4>;
		reg-io-width = <0x04>;
		rockchip,grf = <0xad>;
		rockchip,vo1_grf = <0xbd>;
		phys = <0xe5>;
		phy-names = "hdmi";
		#sound-dai-cells = <0x00>;
		status = "okay";
		enable-gpios = <0xe6 0x09 0x00>;
		phandle = <0x1af>;

		ports {
			#address-cells = <0x01>;
			#size-cells = <0x00>;

			port@0 {
				reg = <0x00>;
				#address-cells = <0x01>;
				#size-cells = <0x00>;

				endpoint@0 {
					reg = <0x00>;
					remote-endpoint = <0x35>;
					status = "okay";
					phandle = <0xc1>;
				};
			};
		};
	};

	ethernet@fe1c0000 {
		local-mac-address = [90 e4 68 52 8e 14];
		compatible = "rockchip,rk3588-gmac\0snps,dwmac-4.20a";
		reg = <0x00 0xfe1c0000 0x00 0x10000>;
		interrupts = <0x00 0xea 0x04 0x00 0xe9 0x04>;
		interrupt-names = "macirq\0eth_wake_irq";
		rockchip,grf = <0xad>;
		rockchip,php_grf = <0x5f>;
		clocks = <0x02 0x144 0x02 0x145 0x02 0x168 0x02 0x16d 0x02 0x143>;
		clock-names = "stmmaceth\0clk_mac_ref\0pclk_mac\0aclk_mac\0ptp_ref";
		resets = <0x02 0x20b>;
		reset-names = "stmmaceth";
		power-domains = <0x4c 0x21>;
		snps,mixed-burst;
		snps,tso;
		snps,axi-config = <0xf2>;
		snps,mtl-rx-config = <0xf3>;
		snps,mtl-tx-config = <0xf4>;
		status = "okay";
		phy-mode = "rgmii";
		clock_in_out = "output";
		snps,reset-gpio = <0xf5 0x0f 0x00>;
		snps,reset-active-high;
		snps,reset-delays-us = <0x00 0x3d090 0x7a120>;
		pinctrl-names = "default";
		pinctrl-0 = <0xf6 0xf7 0xf8 0xf9 0xfa>;
		tx_delay = <0x42>;
		rx_delay = <0x4f>;
		fixed-link = <0x01 0x01 0x3e8 0x01 0x01>;

		mdio {
			compatible = "snps,dwmac-mdio";
			#address-cells = <0x01>;
			#size-cells = <0x00>;
			status = "okay";

			phy@1 {
				compatible = "ethernet-phy-ieee802.3-c22";
				reg = <0x01>;
			};
		};

		stmmac-axi-config {
			snps,wr_osr_lmt = <0x04>;
			snps,rd_osr_lmt = <0x08>;
			snps,blen = <0x00 0x00 0x00 0x00 0x10 0x08 0x04>;
			phandle = <0xf2>;
		};

		rx-queues-config {
			snps,rx-queues-to-use = <0x02>;
			phandle = <0xf3>;

			queue0 {
			};

			queue1 {
			};
		};

		tx-queues-config {
			snps,tx-queues-to-use = <0x02>;
			phandle = <0xf4>;

			queue0 {
			};

			queue1 {
			};
		};
	};

	mmc@fe2e0000 {
		compatible = "rockchip,rk3588-dwcmshc\0rockchip,dwcmshc-sdhci";
		reg = <0x00 0xfe2e0000 0x00 0x10000>;
		interrupts = <0x00 0xcd 0x04>;
		assigned-clocks = <0x02 0x13b 0x02 0x13c 0x02 0x13a>;
		assigned-clock-rates = <0xbebc200 0x16e3600 0xbebc200>;
		clocks = <0x02 0x13a 0x02 0x138 0x02 0x139 0x02 0x13b 0x02 0x13c>;
		clock-names = "core\0bus\0axi\0block\0timer";
		resets = <0x02 0x1f6 0x02 0x1f4 0x02 0x1f5 0x02 0x1f7 0x02 0x1f8>;
		reset-names = "core\0bus\0axi\0block\0timer";
		max-frequency = <0xbebc200>;
		status = "okay";
		bus-width = <0x08>;
		no-sdio;
		no-sd;
		non-removable;
		mmc-hs400-1_8v;
		mmc-hs400-enhanced-strobe;
	};

	i2s@fe470000 {
		compatible = "rockchip,rk3588-i2s-tdm";
		reg = <0x00 0xfe470000 0x00 0x1000>;
		interrupts = <0x00 0xb4 0x04>;
		clocks = <0x02 0x33 0x02 0x37 0x02 0x30>;
		clock-names = "mclk_tx\0mclk_rx\0hclk";
		assigned-clocks = <0x02 0x31 0x02 0x35>;
		assigned-clock-parents = <0x02 0x05 0x02 0x05>;
		dmas = <0x62 0x00 0x62 0x01>;
		dma-names = "tx\0rx";
		power-domains = <0x4c 0x26>;
		resets = <0x02 0x77 0x02 0x7a>;
		reset-names = "tx-m\0rx-m";
		rockchip,clk-trcm = <0x01>;
		pinctrl-names = "default";
		pinctrl-0 = <0x101 0x102 0x103>;
		#sound-dai-cells = <0x00>;
		status = "okay";
		phandle = <0x1b2>;
	};

	i2s@fe480000 {
		compatible = "rockchip,rk3588-i2s-tdm";
		reg = <0x00 0xfe480000 0x00 0x1000>;
		interrupts = <0x00 0xb5 0x04>;
		clocks = <0x02 0x28c 0x02 0x290 0x02 0x288>;
		clock-names = "mclk_tx\0mclk_rx\0hclk";
		dmas = <0x62 0x02 0x62 0x03>;
		dma-names = "tx\0rx";
		resets = <0x02 0xc002a 0x02 0xc002d>;
		reset-names = "tx-m\0rx-m";
		rockchip,clk-trcm = <0x01>;
		pinctrl-names = "default";
		pinctrl-0 = <0x104 0x105 0x106 0x107 0x108 0x109 0x10a>;
		#sound-dai-cells = <0x00>;
		status = "okay";
		assigned-clocks = <0x02 0x28f>;
		assigned-clock-parents = <0x02 0x289>;
		phandle = <0x1b5>;
	};

	i2c@fea90000 {
		compatible = "rockchip,rk3588-i2c\0rockchip,rk3399-i2c";
		reg = <0x00 0xfea90000 0x00 0x1000>;
		clocks = <0x02 0x8d 0x02 0x85>;
		clock-names = "i2c\0pclk";
		interrupts = <0x00 0x13e 0x04>;
		pinctrl-names = "default";
		pinctrl-0 = <0x125>;
		#address-cells = <0x01>;
		#size-cells = <0x00>;
		status = "okay";

		rk8602@42 {
			compatible = "rockchip,rk8602";
			reg = <0x42>;
			vin-supply = <0x61>;
			regulator-compatible = "rk860x-reg";
			regulator-name = "vdd_npu_s0";
			regulator-min-microvolt = <0x86470>;
			regulator-max-microvolt = <0xe7ef0>;
			regulator-ramp-delay = <0x8fc>;
			rockchip,suspend-voltage-selector = <0x01>;
			regulator-boot-on;
			regulator-always-on;
			phandle = <0x99>;

			regulator-state-mem {
				regulator-off-in-suspend;
			};
		};
	};

	i2c@feab0000 {
		compatible = "rockchip,rk3588-i2c\0rockchip,rk3399-i2c";
		reg = <0x00 0xfeab0000 0x00 0x1000>;
		clocks = <0x02 0x8f 0x02 0x87>;
		clock-names = "i2c\0pclk";
		interrupts = <0x00 0x140 0x04>;
		pinctrl-names = "default";
		pinctrl-0 = <0x127>;
		#address-cells = <0x01>;
		#size-cells = <0x00>;
		status = "okay";
		clock-frequency = <0x186a0>;

		lt8911exb@29 {
			status = "okay";
			compatible = "lontium,lt8911exb";
			reg = <0x29>;
			bl-on-gpios = <0x128 0x0f 0x00>;
			panel-pwren-gpios = <0x129 0x0b 0x00>;
			bl-pwren-gpios = <0x129 0x0a 0x00>;
			rst-gpios = <0xe6 0x16 0x00>;
			lt-irq-gpios = <0x129 0x15 0x00>;
		};

		acm8265m@2d {
			status = "okay";
			compatible = "ESMT, acm8625m";
			reg = <0x2d>;
			#sound-dai-cells = <0x00>;
			reset_pin = <0xf1 0x12 0x00>;
			no_mclk;
			phandle = <0x1b3>;
		};
	};

	i2c@fead0000 {
		compatible = "rockchip,rk3588-i2c\0rockchip,rk3399-i2c";
		reg = <0x00 0xfead0000 0x00 0x1000>;
		clocks = <0x02 0x91 0x02 0x89>;
		clock-names = "i2c\0pclk";
		interrupts = <0x00 0x142 0x04>;
		pinctrl-names = "default";
		pinctrl-0 = <0x12b>;
		#address-cells = <0x01>;
		#size-cells = <0x00>;
		status = "okay";

		lt6911c_A@2b {
			status = "okay";
			compatible = "lontium,lt6911c";
			reg = <0x2b>;
			clocks = <0x02 0x101>;
			clock-names = "xvclk";
			reset-gpios = <0xe6 0x11 0x00>;
			res-change-gpios = <0xf5 0x14 0x00>;
			plugin-det-gpios = <0xf5 0x19 0x00>;
			rockchip,camera-module-index = <0x00>;
			rockchip,camera-module-facing = "back";
			rockchip,camera-module-name = "lt6911c_A";
			rockchip,camera-module-lens-name = "NC";
			cvte,hdmi-port-name = "HDMIIN1";

			port {

				endpoint {
					remote-endpoint = <0x12c>;
					data-lanes = <0x01 0x02 0x03 0x04>;
					phandle = <0x2a>;
				};
			};
		};

		lt8711uxe1@29 {
			status = "okay";
			compatible = "lontium,lt8711uxe1";
			reg = <0x29>;
			plugin-det-gpios = <0xf5 0x1d 0x00>;
			reset-gpios = <0xf5 0x0e 0x00>;
		};
	};

	timer@feae0000 {
		compatible = "rockchip,rk3588-timer\0rockchip,rk3288-timer";
		reg = <0x00 0xfeae0000 0x00 0x20>;
		interrupts = <0x00 0x121 0x04>;
		clocks = <0x02 0x5c 0x02 0x5f>;
		clock-names = "pclk\0timer";
	};

	watchdog@feaf0000 {
		compatible = "snps,dw-wdt";
		reg = <0x00 0xfeaf0000 0x00 0x100>;
		clocks = <0x02 0x6c 0x02 0x6b>;
		clock-names = "tclk\0pclk";
		interrupts = <0x00 0x13b 0x04>;
		
		status = "disabled";
	};

	spi@feb20000 {
		compatible = "rockchip,rk3066-spi";
		reg = <0x00 0xfeb20000 0x00 0x1000>;
		interrupts = <0x00 0x148 0x04>;
		#address-cells = <0x01>;
		#size-cells = <0x00>;
		clocks = <0x02 0xa5 0x02 0xa0>;
		clock-names = "spiclk\0apb_pclk";
		dmas = <0xd6 0x0f 0xd6 0x10>;
		dma-names = "tx\0rx";
		pinctrl-names = "default";
		pinctrl-0 = <0x133 0x134>;
		num-cs = <0x01>;
		status = "okay";
		assigned-clocks = <0x02 0xa5>;
		assigned-clock-rates = <0xbebc200>;

		rk806single@0 {
			compatible = "rockchip,rk806";
			spi-max-frequency = <0xf4240>;
			reg = <0x00>;
			interrupt-parent = <0x128>;
			interrupts = <0x07 0x08>;
			pinctrl-names = "default\0pmic-power-off";
			pinctrl-0 = <0x135 0x136 0x137 0x138>;
			pinctrl-1 = <0x139 0x137 0x138>;
			low_voltage_threshold = <0xbb8>;
			shutdown_voltage_threshold = <0xa8c>;
			shutdown_temperture_threshold = <0xa0>;
			hotdie_temperture_threshold = <0x73>;
			pmic-reset-func = <0x01>;
			vcc1-supply = <0x61>;
			vcc2-supply = <0x61>;
			vcc3-supply = <0x61>;
			vcc4-supply = <0x61>;
			vcc5-supply = <0x61>;
			vcc6-supply = <0x61>;
			vcc7-supply = <0x61>;
			vcc8-supply = <0x61>;
			vcc9-supply = <0x61>;
			vcc10-supply = <0x61>;
			vcc11-supply = <0x13a>;
			vcc12-supply = <0x61>;
			vcc13-supply = <0x13b>;
			vcc14-supply = <0x13b>;
			vcca-supply = <0x61>;

			pwrkey {
				status = "okay";
			};

			pinctrl_rk806 {
				gpio-controller;
				#gpio-cells = <0x02>;

				rk806_dvs1_null {
					pins = "gpio_pwrctrl2";
					function = "pin_fun0";
					phandle = <0x136>;
				};

				rk806_dvs1_slp {
					pins = "gpio_pwrctrl1";
					function = "pin_fun1";
					phandle = <0x139>;
				};

				rk806_dvs1_pwrdn {
					pins = "gpio_pwrctrl1";
					function = "pin_fun2";
				};

				rk806_dvs1_rst {
					pins = "gpio_pwrctrl1";
					function = "pin_fun3";
				};

				rk806_dvs2_null {
					pins = "gpio_pwrctrl2";
					function = "pin_fun0";
					phandle = <0x137>;
				};

				rk806_dvs2_slp {
					pins = "gpio_pwrctrl2";
					function = "pin_fun1";
				};

				rk806_dvs2_pwrdn {
					pins = "gpio_pwrctrl2";
					function = "pin_fun2";
				};

				rk806_dvs2_rst {
					pins = "gpio_pwrctrl2";
					function = "pin_fun3";
				};

				rk806_dvs2_dvs {
					pins = "gpio_pwrctrl2";
					function = "pin_fun4";
				};

				rk806_dvs2_gpio {
					pins = "gpio_pwrctrl2";
					function = "pin_fun5";
				};

				rk806_dvs3_null {
					pins = "gpio_pwrctrl3";
					function = "pin_fun0";
					phandle = <0x138>;
				};

				rk806_dvs3_slp {
					pins = "gpio_pwrctrl3";
					function = "pin_fun1";
				};

				rk806_dvs3_pwrdn {
					pins = "gpio_pwrctrl3";
					function = "pin_fun2";
				};

				rk806_dvs3_rst {
					pins = "gpio_pwrctrl3";
					function = "pin_fun3";
				};

				rk806_dvs3_dvs {
					pins = "gpio_pwrctrl3";
					function = "pin_fun4";
				};

				rk806_dvs3_gpio {
					pins = "gpio_pwrctrl3";
					function = "pin_fun5";
				};
			};

			regulators {

				DCDC_REG1 {
					regulator-always-on;
					regulator-boot-on;
					regulator-min-microvolt = <0x86470>;
					regulator-max-microvolt = <0xe7ef0>;
					regulator-ramp-delay = <0x30d4>;
					regulator-name = "vdd_gpu_s0";
					phandle = <0x4e>;

					regulator-state-mem {
						regulator-off-in-suspend;
					};
				};

				DCDC_REG2 {
					regulator-always-on;
					regulator-boot-on;
					regulator-min-microvolt = <0x86470>;
					regulator-max-microvolt = <0xe7ef0>;
					regulator-ramp-delay = <0x30d4>;
					regulator-name = "vdd_cpu_lit_s0";
					phandle = <0x1b>;

					regulator-state-mem {
						regulator-off-in-suspend;
					};
				};

				DCDC_REG3 {
					regulator-always-on;
					regulator-boot-on;
					regulator-min-microvolt = <0xb71b0>;
					regulator-max-microvolt = <0xb71b0>;
					regulator-ramp-delay = <0x30d4>;
					regulator-name = "vdd_log_s0";

					regulator-state-mem {
						regulator-on-in-suspend;
					};
				};

				DCDC_REG4 {
					regulator-always-on;
					regulator-boot-on;
					regulator-min-microvolt = <0x86470>;
					regulator-max-microvolt = <0xe7ef0>;
					regulator-init-microvolt = <0xb71b0>;
					regulator-ramp-delay = <0x30d4>;
					regulator-name = "vdd_vdenc_s0";
					phandle = <0xaa>;

					regulator-state-mem {
						regulator-off-in-suspend;
					};
				};

				DCDC_REG5 {
					regulator-always-on;
					regulator-boot-on;
					regulator-min-microvolt = <0xcf850>;
					regulator-max-microvolt = <0xcf850>;
					regulator-ramp-delay = <0x30d4>;
					regulator-name = "vdd_ddr_s0";

					regulator-state-mem {
						regulator-off-in-suspend;
						regulator-suspend-microvolt = <0xcf850>;
					};
				};

				DCDC_REG6 {
					regulator-always-on;
					regulator-boot-on;
					regulator-name = "vdd2_ddr_s3";

					regulator-state-mem {
						regulator-on-in-suspend;
					};
				};

				DCDC_REG7 {
					regulator-always-on;
					regulator-boot-on;
					regulator-min-microvolt = <0x1e8480>;
					regulator-max-microvolt = <0x1e8480>;
					regulator-name = "vdd_2v0_pldo_s3";
					phandle = <0x13a>;

					regulator-state-mem {
						regulator-on-in-suspend;
						regulator-suspend-microvolt = <0x1e8480>;
					};
				};

				DCDC_REG8 {
					regulator-always-on;
					regulator-boot-on;
					regulator-min-microvolt = <0x325aa0>;
					regulator-max-microvolt = <0x325aa0>;
					regulator-name = "vcc_3v3_s3";

					regulator-state-mem {
						regulator-on-in-suspend;
					};
				};

				DCDC_REG9 {
					regulator-always-on;
					regulator-boot-on;
					regulator-name = "vddq_ddr_s0";

					regulator-state-mem {
						regulator-off-in-suspend;
					};
				};

				DCDC_REG10 {
					regulator-always-on;
					regulator-boot-on;
					regulator-min-microvolt = <0x1b7740>;
					regulator-max-microvolt = <0x1b7740>;
					regulator-name = "vcc_1v8_s3";

					regulator-state-mem {
						regulator-on-in-suspend;
						regulator-suspend-microvolt = <0x1b7740>;
					};
				};

				PLDO_REG1 {
					regulator-always-on;
					regulator-boot-on;
					regulator-min-microvolt = <0x1b7740>;
					regulator-max-microvolt = <0x1b7740>;
					regulator-name = "avcc_1v8_s0";
					phandle = <0x156>;

					regulator-state-mem {
						regulator-off-in-suspend;
						regulator-on-in-suspend;
						regulator-suspend-microvolt = <0x1b7740>;
					};
				};

				PLDO_REG2 {
					regulator-always-on;
					regulator-boot-on;
					regulator-min-microvolt = <0x1b7740>;
					regulator-max-microvolt = <0x1b7740>;
					regulator-name = "vcc_1v8_s0";

					regulator-state-mem {
						regulator-off-in-suspend;
						regulator-suspend-microvolt = <0x1b7740>;
					};
				};

				PLDO_REG3 {
					regulator-always-on;
					regulator-boot-on;
					regulator-min-microvolt = <0x124f80>;
					regulator-max-microvolt = <0x124f80>;
					regulator-name = "avdd_1v2_s0";

					regulator-state-mem {
						regulator-off-in-suspend;
					};
				};

				PLDO_REG4 {
					regulator-always-on;
					regulator-boot-on;
					regulator-min-microvolt = <0x325aa0>;
					regulator-max-microvolt = <0x325aa0>;
					regulator-name = "vcc_3v3_s0";

					regulator-state-mem {
						regulator-off-in-suspend;
					};
				};

				PLDO_REG5 {
					regulator-always-on;
					regulator-boot-on;
					regulator-min-microvolt = <0x1b7740>;
					regulator-max-microvolt = <0x325aa0>;
					regulator-name = "vccio_sd_s0";

					regulator-state-mem {
						regulator-off-in-suspend;
					};
				};

				PLDO_REG6 {
					regulator-always-on;
					regulator-boot-on;
					regulator-min-microvolt = <0x1b7740>;
					regulator-max-microvolt = <0x1b7740>;
					regulator-name = "pldo6_s3";

					regulator-state-mem {
						regulator-on-in-suspend;
						regulator-suspend-microvolt = <0x1b7740>;
					};
				};

				NLDO_REG1 {
					regulator-always-on;
					regulator-boot-on;
					regulator-min-microvolt = <0xb71b0>;
					regulator-max-microvolt = <0xb71b0>;
					regulator-name = "vdd_0v75_s3";

					regulator-state-mem {
						regulator-on-in-suspend;
						regulator-suspend-microvolt = <0xb71b0>;
					};
				};

				NLDO_REG2 {
					regulator-always-on;
					regulator-boot-on;
					regulator-min-microvolt = <0xcf850>;
					regulator-max-microvolt = <0xcf850>;
					regulator-name = "vdd_ddr_pll_s0";

					regulator-state-mem {
						regulator-off-in-suspend;
						regulator-suspend-microvolt = <0xcf850>;
					};
				};

				NLDO_REG3 {
					regulator-always-on;
					regulator-boot-on;
					regulator-min-microvolt = <0xcc77c>;
					regulator-max-microvolt = <0xcc77c>;
					regulator-name = "avdd_0v75_s0";

					regulator-state-mem {
						regulator-off-in-suspend;
					};
				};

				NLDO_REG4 {
					regulator-always-on;
					regulator-boot-on;
					regulator-min-microvolt = <0xcf850>;
					regulator-max-microvolt = <0xcf850>;
					regulator-name = "vdd_0v85_s0";

					regulator-state-mem {
						regulator-off-in-suspend;
					};
				};

				NLDO_REG5 {
					regulator-name = "nldo5_s0";
					regulator-always-on;
					regulator-boot-on;
					regulator-min-microvolt = <0xb71b0>;
					regulator-max-microvolt = <0xb71b0>;
					rregulator-name = "nldo5_s0";
					phandle = <0x1b7>;

					regulator-state-mem {
						regulator-off-in-suspend;
					};
				};
			};
		};
	};

	serial@feb80000 {
		compatible = "rockchip,rk3588-uart\0snps,dw-apb-uart";
		reg = <0x00 0xfeb80000 0x00 0x100>;
		interrupts = <0x00 0x150 0x04>;
		clocks = <0x02 0xc7 0x02 0xaf>;
		clock-names = "baudclk\0apb_pclk";
		reg-shift = <0x02>;
		reg-io-width = <0x04>;
		dmas = <0xd6 0x0b 0xd6 0x0c>;
		pinctrl-names = "default";
		pinctrl-0 = <0x143>;
		status = "okay";
	};

	tsadc@fec00000 {
		compatible = "rockchip,rk3588-tsadc";
		reg = <0x00 0xfec00000 0x00 0x400>;
		interrupts = <0x00 0x18d 0x04>;
		clocks = <0x02 0xaa 0x02 0xa9>;
		clock-names = "tsadc\0apb_pclk";
		assigned-clocks = <0x02 0xaa>;
		assigned-clock-rates = <0x1e8480>;
		resets = <0x02 0xc1 0x02 0xc0>;
		reset-names = "tsadc\0tsadc-apb";
		#thermal-sensor-cells = <0x01>;
		rockchip,hw-tshut-temp = <0x1d4c0>;
		rockchip,hw-tshut-mode = <0x00>;
		rockchip,hw-tshut-polarity = <0x00>;
		pinctrl-names = "gpio\0otpout";
		pinctrl-0 = <0x154>;
		pinctrl-1 = <0x155>;
		status = "okay";
		phandle = <0x49>;
	};

	saradc@fec10000 {
		compatible = "rockchip,rk3588-saradc";
		reg = <0x00 0xfec10000 0x00 0x10000>;
		interrupts = <0x00 0x18e 0x04>;
		#io-channel-cells = <0x01>;
		clocks = <0x02 0x9d 0x02 0x9c>;
		clock-names = "saradc\0apb_pclk";
		resets = <0x02 0xbe>;
		reset-names = "saradc-apb";
		status = "okay";
		vref-supply = <0x156>;
		phandle = <0x1a9>;
	};

	i2c@fec80000 {
		compatible = "rockchip,rk3588-i2c\0rockchip,rk3399-i2c";
		reg = <0x00 0xfec80000 0x00 0x1000>;
		clocks = <0x02 0x92 0x02 0x8a>;
		clock-names = "i2c\0pclk";
		interrupts = <0x00 0x143 0x04>;
		pinctrl-names = "default";
		pinctrl-0 = <0x157>;
		#address-cells = <0x01>;
		#size-cells = <0x00>;
		status = "okay";

		lt6911c_B@2b {
			status = "okay";
			compatible = "lontium,lt6911c";
			reg = <0x2b>;
			clocks = <0x02 0x103>;
			clock-names = "xvclk";
			reset-gpios = <0xf5 0x1a 0x00>;
			res-change-gpios = <0xf5 0x1b 0x00>;
			plugin-det-gpios = <0xf5 0x1c 0x00>;
			rockchip,camera-module-index = <0x01>;
			rockchip,camera-module-facing = "back";
			rockchip,camera-module-name = "lt6911c_B";
			rockchip,camera-module-lens-name = "NC";
			cvte,hdmi-port-name = "HDMIIN2";

			port {
				endpoint {
					remote-endpoint = <0x158>;
					data-lanes = <0x01 0x02 0x03 0x04>;
					phandle = <0x179>;
				};
			};
		};

		et7304@4e {
			compatible = "etek,et7303";
			reg = <0x4e>;
			interrupt-parent = <0x129>;
			interrupts = <0x06 0x08>;
			pinctrl-names = "default";
			pinctrl-0 = <0x159>;
			vbus-supply = <0x5d>;
			status = "okay";

			ports {
				#address-cells = <0x01>;
				#size-cells = <0x00>;

				port@0 {
					reg = <0x00>;

					endpoint@0 {
						remote-endpoint = <0x15a>;
						phandle = <0x53>;
					};
				};
			};

			connector {
				compatible = "usb-c-connector";
				label = "USB-C";
				data-role = "dual";
				power-role = "dual";
				try-power-role = "sink";
				op-sink-microwatt = <0xf4240>;
				sink-pdos = <0x4019064>;
				source-pdos = <0x401912c>;

				altmodes {
					#address-cells = <0x01>;
					#size-cells = <0x00>;

					altmode@0 {
						reg = <0x00>;
						svid = <0xff01>;
						vdo = <0xffffffff>;
					};
				};

				ports {
					#address-cells = <0x01>;
					#size-cells = <0x00>;

					port@0 {
						reg = <0x00>;

						endpoint {
							remote-endpoint = <0x15b>;
							phandle = <0x166>;
						};
					};

					port@1 {
						reg = <0x01>;

						endpoint {
							remote-endpoint = <0x15c>;
							phandle = <0x167>;
						};
					};
				};
			};
		};
	};

	dma-controller@fed10000 {
		compatible = "arm,pl330\0arm,primecell";
		reg = <0x00 0xfed10000 0x00 0x4000>;
		interrupts = <0x00 0x5a 0x04 0x00 0x5b 0x04>;
		clocks = <0x02 0x7a>;
		clock-names = "apb_pclk";
		#dma-cells = <0x01>;
		arm,pl330-periph-burst;
		phandle = <0xd7>;
	};

	phy@fed80000 {
		compatible = "rockchip,rk3588-usbdp-phy";
		reg = <0x00 0xfed80000 0x00 0x10000>;
		rockchip,u2phy-grf = <0x163>;
		rockchip,usb-grf = <0x5c>;
		rockchip,usbdpphy-grf = <0x164>;
		rockchip,vo-grf = <0xdd>;
		clocks = <0x02 0x2b6 0x02 0x27f 0x02 0x269 0x165>;
		clock-names = "refclk\0immortal\0pclk\0utmi";
		resets = <0x02 0x28 0x02 0x29 0x02 0x2a 0x02 0x2b 0x02 0x482>;
		reset-names = "init\0cmn\0lane\0pcs_apb\0pma_apb";
		status = "okay";
		orientation-switch;
		svid = <0xff01>;
		sbu1-dc-gpios = <0x128 0x16 0x00>;
		sbu2-dc-gpios = <0x128 0x1b 0x00>;

		dp-port {
			#phy-cells = <0x00>;
			status = "okay";
			phandle = <0xde>;
		};

		u3-port {
			#phy-cells = <0x00>;
			status = "okay";
			phandle = <0x52>;
		};

		port {
			#address-cells = <0x01>;
			#size-cells = <0x00>;

			endpoint@0 {
				reg = <0x00>;
				remote-endpoint = <0x166>;
				phandle = <0x15b>;
			};

			endpoint@1 {
				reg = <0x01>;
				remote-endpoint = <0x167>;
				phandle = <0x15c>;
			};
		};
	};

	usbdrd3_1 {
		compatible = "rockchip,rk3588-dwc3\0rockchip,rk3399-dwc3";
		clocks = <0x02 0x1a6 0x02 0x1a5 0x02 0x1a4>;
		clock-names = "ref\0suspend\0bus";
		#address-cells = <0x02>;
		#size-cells = <0x02>;
		ranges;
		status = "okay";

		usb@fc400000 {
			compatible = "snps,dwc3";
			reg = <0x00 0xfc400000 0x00 0x400000>;
			interrupts = <0x00 0xdd 0x04>;
			power-domains = <0x4c 0x1f>;
			resets = <0x02 0x2a7>;
			reset-names = "usb3-otg";
			dr_mode = "host";
			phys = <0x17e 0x17f>;
			phy-names = "usb2-phy\0usb3-phy";
			phy_type = "utmi_wide";
			snps,dis_enblslpm_quirk;
			snps,dis-u2-freeclk-exists-quirk;
			snps,dis-del-phy-power-chg-quirk;
			snps,dis-tx-ipgap-linecheck-quirk;
			snps,parkmode-disable-ss-quirk;
			status = "okay";
		};
	};

	syscon@fd5b8000 {
		compatible = "rockchip,pcie30-phy-grf\0syscon";
		reg = <0x00 0xfd5b8000 0x00 0x10000>;
		phandle = <0x1a8>;
	};

	syscon@fd5cc000 {
		compatible = "rockchip,rk3588-usbdpphy-grf\0syscon";
		reg = <0x00 0xfd5cc000 0x00 0x4000>;
		phandle = <0x1a3>;
	};

	syscon@fd5d4000 {
		compatible = "rockchip,rk3588-usb2phy-grf\0syscon\0simple-mfd";
		reg = <0x00 0xfd5d4000 0x00 0x4000>;
		#address-cells = <0x01>;
		#size-cells = <0x01>;
		phandle = <0x1a2>;

		usb2-phy@4000 {
			compatible = "rockchip,rk3588-usb2phy";
			reg = <0x4000 0x10>;
			interrupts = <0x00 0x18a 0x04>;
			resets = <0x02 0xc0048 0x02 0x489>;
			reset-names = "phy\0apb";
			clocks = <0x02 0x2b5>;
			clock-names = "phyclk";
			clock-output-names = "usb480m_phy1";
			#clock-cells = <0x00>;
			rockchip,usbctrl-grf = <0x5c>;
			status = "okay";
			phandle = <0x1a4>;

			otg-port {
				#phy-cells = <0x00>;
				status = "okay";
				phy-supply = <0x5e>;
				phandle = <0x17e>;
			};
		};
	};

	hdmi@fdea0000 {
		compatible = "rockchip,rk3588-dw-hdmi";
		reg = <0x00 0xfdea0000 0x00 0x20000>;
		interrupts = <0x00 0xad 0x04 0x00 0xae 0x04 0x00 0xaf 0x04 0x00 0xb0 0x04 0x00 0x169 0x04>;
		clocks = <0x02 0x224 0x02 0x266 0x02 0x225 0x02 0x226 0x02 0x24c 0x02 0x274 0x02 0x275 0x02 0x276 0x02 0x277 0x05 0x2f>;
		clock-names = "pclk\0hpd\0earc\0hdmitx_ref\0aud\0dclk_vp0\0dclk_vp1\0dclk_vp2\0dclk_vp3\0hclk_vo1\0link_clk";
		resets = <0x02 0x3d7 0x02 0x49d>;
		reset-names = "ref\0hdp";
		power-domains = <0x4c 0x1a>;
		pinctrl-names = "default";
		pinctrl-0 = <0x186 0x187 0x188>;
		reg-io-width = <0x04>;
		rockchip,grf = <0xad>;
		rockchip,vo1_grf = <0xbd>;
		phys = <0x189>;
		phy-names = "hdmi";
		#sound-dai-cells = <0x00>;
		status = "okay";
		enable-gpios = <0xe6 0x0a 0x00>;
		phandle = <0x1b1>;

		ports {
			#address-cells = <0x01>;
			#size-cells = <0x00>;

			port@0 {
				reg = <0x00>;
				#address-cells = <0x01>;
				#size-cells = <0x00>;

				endpoint@1 {
					reg = <0x01>;
					remote-endpoint = <0x38>;
					status = "okay";
					phandle = <0xca>;
				};
			};
		};
	};

	pcie@fe150000 {
		compatible = "rockchip,rk3588-pcie\0snps,dw-pcie";
		#address-cells = <0x03>;
		#size-cells = <0x02>;
		bus-range = <0x00 0x0f>;
		clocks = <0x02 0x14e 0x02 0x153 0x02 0x149 0x02 0x158 0x02 0x15e 0x02 0x183>;
		clock-names = "aclk_mst\0aclk_slv\0aclk_dbi\0pclk\0aux\0pipe";
		device_type = "pci";
		interrupts = <0x00 0x107 0x04 0x00 0x106 0x04 0x00 0x105 0x04 0x00 0x104 0x04 0x00 0x103 0x04>;
		interrupt-names = "sys\0pmc\0msg\0legacy\0err";
		#interrupt-cells = <0x01>;
		interrupt-map-mask = <0x00 0x00 0x00 0x07>;
		interrupt-map = <0x00 0x00 0x00 0x01 0x191 0x00 0x00 0x00 0x00 0x02 0x191 0x01 0x00 0x00 0x00 0x03 0x191 0x02 0x00 0x00 0x00 0x04 0x191 0x03>;
		linux,pci-domain = <0x00>;
		num-ib-windows = <0x10>;
		num-ob-windows = <0x10>;
		num-viewport = <0x08>;
		max-link-speed = <0x03>;
		msi-map = <0x00 0x192 0x00 0x1000>;
		num-lanes = <0x04>;
		phys = <0x193>;
		phy-names = "pcie-phy";
		power-domains = <0x4c 0x22>;
		ranges = <0x800 0x00 0xf0000000 0x00 0xf0000000 0x00 0x100000 0x81000000 0x00 0xf0100000 0x00 0xf0100000 0x00 0x100000 0x82000000 0x00 0xf0200000 0x00 0xf0200000 0x00 0xe00000 0xc3000000 0x09 0x00 0x09 0x00 0x00 0x40000000>;
		reg = <0x00 0xfe150000 0x00 0x10000 0x0a 0x40000000 0x00 0x400000>;
		reg-names = "pcie-apb\0pcie-dbi";
		resets = <0x02 0x20d 0x02 0x21c>;
		reset-names = "pcie\0periph";
		rockchip,pipe-grf = <0x5f>;
		status = "okay";
		reset-gpios = <0xf1 0x0a 0x00>;
		vpcie3v3-supply = <0x194>;

		legacy-interrupt-controller {
			interrupt-controller;
			#address-cells = <0x00>;
			#interrupt-cells = <0x01>;
			interrupt-parent = <0x01>;
			interrupts = <0x00 0x104 0x01>;
			phandle = <0x191>;
		};
	};

	phy@fed90000 {
		compatible = "rockchip,rk3588-usbdp-phy";
		reg = <0x00 0xfed90000 0x00 0x10000>;
		rockchip,u2phy-grf = <0x1a2>;
		rockchip,usb-grf = <0x5c>;
		rockchip,usbdpphy-grf = <0x1a3>;
		rockchip,vo-grf = <0xdd>;
		clocks = <0x02 0x2b6 0x02 0x280 0x02 0x26a 0x1a4>;
		clock-names = "refclk\0immortal\0pclk\0utmi";
		resets = <0x02 0x2f 0x02 0x30 0x02 0x31 0x02 0x32 0x02 0x484>;
		reset-names = "init\0cmn\0lane\0pcs_apb\0pma_apb";
		status = "okay";
		rockchip,dp-lane-mux = <0x02 0x03>;

		dp-port {
			#phy-cells = <0x00>;
			status = "okay";
			phandle = <0x182>;
		};

		u3-port {
			#phy-cells = <0x00>;
			status = "okay";
			phandle = <0x17f>;
		};
	};

	phy@fee80000 {
		compatible = "rockchip,rk3588-pcie3-phy";
		reg = <0x00 0xfee80000 0x00 0x20000>;
		#phy-cells = <0x00>;
		clocks = <0x02 0x188>;
		clock-names = "pclk";
		resets = <0x02 0x2000a>;
		reset-names = "phy";
		rockchip,pipe-grf = <0x5f>;
		rockchip,phy-grf = <0x1a8>;
		status = "okay";
		rockchip,pcie30-phymode = <0x04>;
		phandle = <0x193>;
	};

	adc-keys {
		compatible = "adc-keys";
		io-channels = <0x1a9 0x01>;
		io-channel-names = "buttons";
		keyup-threshold-microvolt = <0x1b7740>;
		poll-interval = <0x64>;

		vol-up-key {
			label = "volume up";
			linux,code = <0x73>;
			press-threshold-microvolt = <0x6d6>;
		};
	};

	test-power {
		status = "okay";
	};

	adcpower-keys {
		compatible = "adc-keys";
		io-channels = <0x1a9 0x03>;
		io-channel-names = "buttons";
		keyup-threshold-microvolt = <0x1b7740>;
		poll-interval = <0x64>;
		status = "okay";

		adc-power-key {
			label = "power key";
			linux,code = <0x74>;
			press-threshold-microvolt = <0x2f198>;
		};
	};

	pcie30-avdd0v75 {
		compatible = "regulator-fixed";
		regulator-name = "pcie30_avdd0v75";
		regulator-boot-on;
		regulator-always-on;
		regulator-min-microvolt = <0xb71b0>;
		regulator-max-microvolt = <0xb71b0>;
		vin-supply = <0x1b7>;
	};

	pcie30-avdd1v8 {
		compatible = "regulator-fixed";
		regulator-name = "pcie30_avdd1v8";
		regulator-boot-on;
		regulator-always-on;
		regulator-min-microvolt = <0x1b7740>;
		regulator-max-microvolt = <0x1b7740>;
		vin-supply = <0x156>;
	};

	vcc12v-dcin {
		compatible = "regulator-fixed";
		regulator-name = "vcc12v_dcin";
		regulator-always-on;
		regulator-boot-on;
		regulator-min-microvolt = <0xb71b00>;
		regulator-max-microvolt = <0xb71b00>;
		phandle = <0x1b8>;
	};

	vcc3v3-pcie30 {
		compatible = "regulator-fixed";
		regulator-name = "vcc3v3_pcie30";
		regulator-min-microvolt = <0x325aa0>;
		regulator-max-microvolt = <0x325aa0>;
		enable-active-high;
		gpios = <0xe6 0x12 0x00>;
		startup-delay-us = <0x1d4c>;
		vin-supply = <0x1b8>;
		phandle = <0x194>;
	};

	vcc5v0-sys {
		compatible = "regulator-fixed";
		regulator-name = "vcc5v0_sys";
		regulator-always-on;
		regulator-boot-on;
		regulator-min-microvolt = <0x4c4b40>;
		regulator-max-microvolt = <0x4c4b40>;
		vin-supply = <0x1b8>;
		phandle = <0x61>;
	};

	vcc5v0-host-regulator {
		compatible = "regulator-fixed";
		regulator-name = "vcc5v0_host";
		regulator-boot-on;
		regulator-always-on;
		regulator-min-microvolt = <0x4c4b40>;
		regulator-max-microvolt = <0x4c4b40>;
		enable-active-high;
		gpio = <0xe6 0x08 0x00>;
		vin-supply = <0x61>;
		pinctrl-names = "default";
		pinctrl-0 = <0x1b9>;
		phandle = <0x5e>;
	};

	vcc5v0-otg-regulator {
		compatible = "regulator-fixed";
		regulator-name = "vcc5v0_otg";
		regulator-min-microvolt = <0x4c4b40>;
		regulator-max-microvolt = <0x4c4b40>;
		enable-active-high;
		gpio = <0xe6 0x03 0x00>;
		vin-supply = <0x61>;
		pinctrl-names = "default";
		pinctrl-0 = <0x1ba>;
		phandle = <0x5d>;
	};

	vcc-1v1-nldo-s3 {
		compatible = "regulator-fixed";
		regulator-name = "vcc_1v1_nldo_s3";
		regulator-always-on;
		regulator-boot-on;
		regulator-min-microvolt = <0x10c8e0>;
		regulator-max-microvolt = <0x10c8e0>;
		vin-supply = <0x61>;
		phandle = <0x13b>;
	};

	fiq-debugger {
		compatible = "rockchip,fiq-debugger";
		rockchip,serial-id = <0x02>;
		rockchip,wake-irq = <0x00>;
		rockchip,irq-mode-enable = <0x01>;
		rockchip,baudrate = <0x16e360>;
		interrupts = <0x00 0x1a7 0x08>;
		pinctrl-names = "default";
		pinctrl-0 = <0x1bd>;
		status = "okay";
	};

	reserved-memory {
		#address-cells = <0x02>;
		#size-cells = <0x02>;
		ranges;

		cma {
			compatible = "shared-dma-pool";
			reusable;
			size = <0x00 0x10000000>;
			linux,cma-default;
		};

		drm-logo@00000000 {
			compatible = "rockchip,drm-logo";
			reg = <0x00 0xedf00000 0x00 0x73800>;
			phandle = <0x30>;
		};

		drm-cubic-lut@00000000 {
			compatible = "rockchip,drm-cubic-lut";
			reg = <0x00 0x00 0x00 0x00>;
		};
	};
};
